VERSION ""

NS_ :

BS_:

BU_: _04_HV_AMS

BO_ 3221225472 VECTOR__INDEPENDENT_SIG_MSG: 0 Vector__XXX
 SG_ AMS_Stack_09_Slave_Cell_Temp_3 : 0|16@0+ (0.1,0) [15|60] "C" Vector__XXX
 SG_ AMS_Stack_09_Slave_Cell_Temp_2 : 0|16@0+ (0.1,0) [15|60] "C" Vector__XXX
 SG_ AMS_Stack_09_Slave_Cell_Temp_1 : 0|16@0+ (0.1,0) [15|60] "C" Vector__XXX
 SG_ AMS_Stack_09_Slave_Cell_Temp_0 : 0|16@0+ (0.1,0) [15|60] "C" Vector__XXX
 SG_ AMS_Stack_10_Slave_Cell_Temp_3 : 0|16@0+ (0.1,0) [15|60] "C" Vector__XXX
 SG_ AMS_Stack_10_Slave_Cell_Temp_2 : 0|16@0+ (0.1,0) [15|60] "C" Vector__XXX
 SG_ AMS_Stack_10_Slave_Cell_Temp_1 : 0|16@0+ (0.1,0) [15|60] "C" Vector__XXX
 SG_ AMS_Stack_10_Slave_Cell_Temp_0 : 0|16@0+ (0.1,0) [15|60] "C" Vector__XXX
 SG_ AMS_Stack_11_Slave_Cell_Temp_3 : 0|16@0+ (0.1,0) [15|60] "C" Vector__XXX
 SG_ AMS_Stack_11_Slave_Cell_Temp_2 : 0|16@0+ (0.1,0) [15|60] "C" Vector__XXX
 SG_ AMS_Stack_11_Slave_Cell_Temp_1 : 0|16@0+ (0.1,0) [15|60] "C" Vector__XXX
 SG_ AMS_Stack_11_Slave_Cell_Temp_0 : 0|16@0+ (0.1,0) [15|60] "C" Vector__XXX

BO_ 1485 AMS_Temps_Stack_08_02: 4 Vector__XXX
 SG_ AMS_Stack_08_Slave_Cell_Temp_5 : 23|16@0+ (0.1,0) [15|60] "C" Vector__XXX
 SG_ AMS_Stack_08_Slave_Cell_Temp_4 : 7|16@0+ (0.1,0) [15|60] "C" Vector__XXX

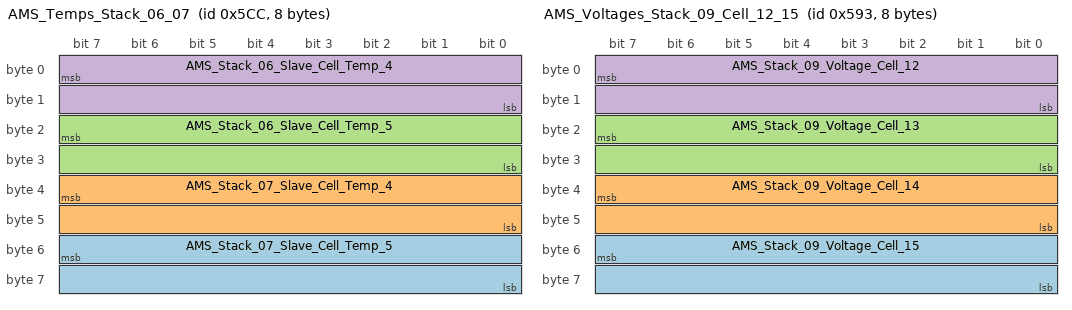
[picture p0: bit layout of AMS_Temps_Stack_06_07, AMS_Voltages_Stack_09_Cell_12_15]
BO_ 1484 AMS_Temps_Stack_06_07: 8 Vector__XXX
 SG_ AMS_Stack_07_Slave_Cell_Temp_5 : 55|16@0+ (0.1,0) [15|60] "C" Vector__XXX
 SG_ AMS_Stack_07_Slave_Cell_Temp_4 : 39|16@0+ (0.1,0) [15|60] "C" Vector__XXX
 SG_ AMS_Stack_06_Slave_Cell_Temp_5 : 23|16@0+ (0.1,0) [15|60] "C" Vector__XXX
 SG_ AMS_Stack_06_Slave_Cell_Temp_4 : 7|16@0+ (0.1,0) [15|60] "C" Vector__XXX

BO_ 1427 AMS_Voltages_Stack_09_Cell_12_15: 8 _04_HV_AMS
 SG_ AMS_Stack_09_Voltage_Cell_15 : 55|16@0- (1,0) [0|0] "mV" Vector__XXX
 SG_ AMS_Stack_09_Voltage_Cell_14 : 39|16@0- (1,0) [0|0] "mV" Vector__XXX
 SG_ AMS_Stack_09_Voltage_Cell_13 : 23|16@0- (1,0) [0|0] "mV" Vector__XXX
 SG_ AMS_Stack_09_Voltage_Cell_12 : 7|16@0- (1,0) [0|0] "mV" Vector__XXX

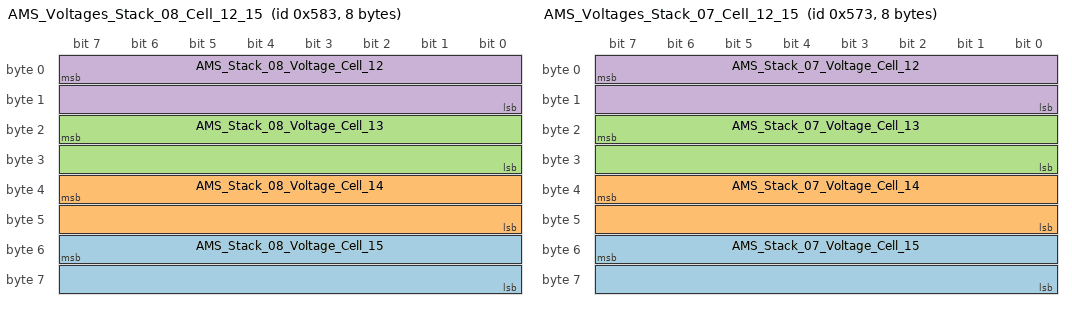
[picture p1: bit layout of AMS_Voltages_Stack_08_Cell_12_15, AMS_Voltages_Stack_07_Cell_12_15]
BO_ 1411 AMS_Voltages_Stack_08_Cell_12_15: 8 _04_HV_AMS
 SG_ AMS_Stack_08_Voltage_Cell_15 : 55|16@0- (1,0) [0|0] "mV" Vector__XXX
 SG_ AMS_Stack_08_Voltage_Cell_14 : 39|16@0- (1,0) [0|0] "mV" Vector__XXX
 SG_ AMS_Stack_08_Voltage_Cell_13 : 23|16@0- (1,0) [0|0] "mV" Vector__XXX
 SG_ AMS_Stack_08_Voltage_Cell_12 : 7|16@0- (1,0) [0|0] "mV" Vector__XXX

BO_ 1395 AMS_Voltages_Stack_07_Cell_12_15: 8 _04_HV_AMS
 SG_ AMS_Stack_07_Voltage_Cell_15 : 55|16@0- (1,0) [0|0] "mV" Vector__XXX
 SG_ AMS_Stack_07_Voltage_Cell_14 : 39|16@0- (1,0) [0|0] "mV" Vector__XXX
 SG_ AMS_Stack_07_Voltage_Cell_13 : 23|16@0- (1,0) [0|0] "mV" Vector__XXX
 SG_ AMS_Stack_07_Voltage_Cell_12 : 7|16@0- (1,0) [0|0] "mV" Vector__XXX

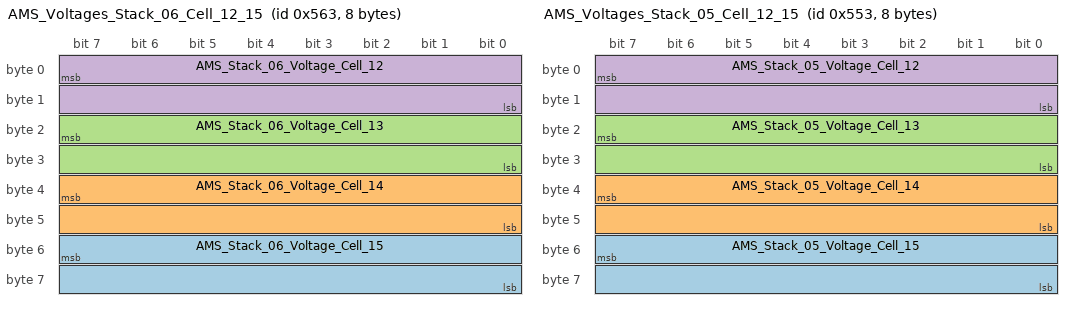
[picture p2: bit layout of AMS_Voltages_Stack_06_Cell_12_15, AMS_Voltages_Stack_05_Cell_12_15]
BO_ 1379 AMS_Voltages_Stack_06_Cell_12_15: 8 _04_HV_AMS
 SG_ AMS_Stack_06_Voltage_Cell_15 : 55|16@0- (1,0) [0|0] "mV" Vector__XXX
 SG_ AMS_Stack_06_Voltage_Cell_14 : 39|16@0- (1,0) [0|0] "mV" Vector__XXX
 SG_ AMS_Stack_06_Voltage_Cell_13 : 23|16@0- (1,0) [0|0] "mV" Vector__XXX
 SG_ AMS_Stack_06_Voltage_Cell_12 : 7|16@0- (1,0) [0|0] "mV" Vector__XXX

BO_ 1363 AMS_Voltages_Stack_05_Cell_12_15: 8 _04_HV_AMS
 SG_ AMS_Stack_05_Voltage_Cell_15 : 55|16@0- (1,0) [0|0] "mV" Vector__XXX
 SG_ AMS_Stack_05_Voltage_Cell_14 : 39|16@0- (1,0) [0|0] "mV" Vector__XXX
 SG_ AMS_Stack_05_Voltage_Cell_13 : 23|16@0- (1,0) [0|0] "mV" Vector__XXX
 SG_ AMS_Stack_05_Voltage_Cell_12 : 7|16@0- (1,0) [0|0] "mV" Vector__XXX

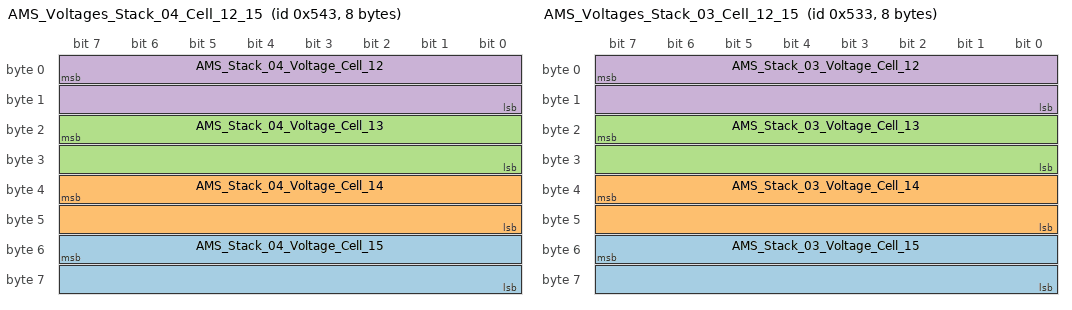
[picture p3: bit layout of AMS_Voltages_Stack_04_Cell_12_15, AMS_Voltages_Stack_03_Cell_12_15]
BO_ 1347 AMS_Voltages_Stack_04_Cell_12_15: 8 _04_HV_AMS
 SG_ AMS_Stack_04_Voltage_Cell_15 : 55|16@0- (1,0) [0|0] "mV" Vector__XXX
 SG_ AMS_Stack_04_Voltage_Cell_14 : 39|16@0- (1,0) [0|0] "mV" Vector__XXX
 SG_ AMS_Stack_04_Voltage_Cell_13 : 23|16@0- (1,0) [0|0] "mV" Vector__XXX
 SG_ AMS_Stack_04_Voltage_Cell_12 : 7|16@0- (1,0) [0|0] "mV" Vector__XXX

BO_ 1331 AMS_Voltages_Stack_03_Cell_12_15: 8 _04_HV_AMS
 SG_ AMS_Stack_03_Voltage_Cell_15 : 55|16@0- (1,0) [0|0] "mV" Vector__XXX
 SG_ AMS_Stack_03_Voltage_Cell_14 : 39|16@0- (1,0) [0|0] "mV" Vector__XXX
 SG_ AMS_Stack_03_Voltage_Cell_13 : 23|16@0- (1,0) [0|0] "mV" Vector__XXX
 SG_ AMS_Stack_03_Voltage_Cell_12 : 7|16@0- (1,0) [0|0] "mV" Vector__XXX

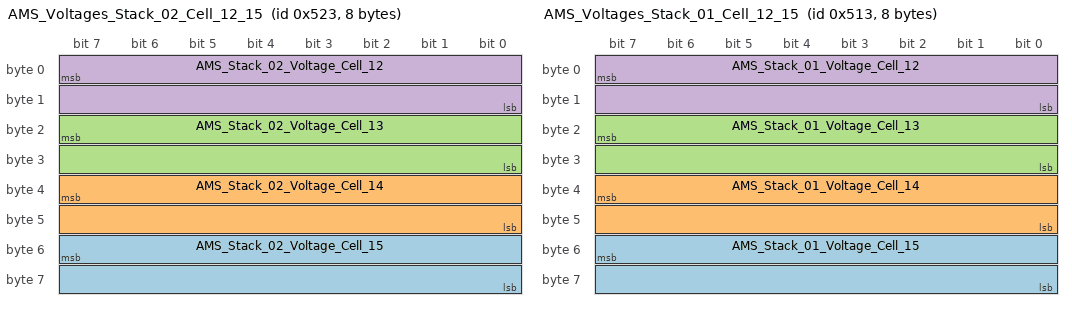
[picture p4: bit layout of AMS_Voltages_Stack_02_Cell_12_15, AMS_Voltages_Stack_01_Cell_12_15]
BO_ 1315 AMS_Voltages_Stack_02_Cell_12_15: 8 _04_HV_AMS
 SG_ AMS_Stack_02_Voltage_Cell_15 : 55|16@0- (1,0) [0|0] "mV" Vector__XXX
 SG_ AMS_Stack_02_Voltage_Cell_14 : 39|16@0- (1,0) [0|0] "mV" Vector__XXX
 SG_ AMS_Stack_02_Voltage_Cell_13 : 23|16@0- (1,0) [0|0] "mV" Vector__XXX
 SG_ AMS_Stack_02_Voltage_Cell_12 : 7|16@0- (1,0) [0|0] "mV" Vector__XXX

BO_ 1299 AMS_Voltages_Stack_01_Cell_12_15: 8 _04_HV_AMS
 SG_ AMS_Stack_01_Voltage_Cell_15 : 55|16@0- (1,0) [0|0] "mV" Vector__XXX
 SG_ AMS_Stack_01_Voltage_Cell_14 : 39|16@0- (1,0) [0|0] "mV" Vector__XXX
 SG_ AMS_Stack_01_Voltage_Cell_13 : 23|16@0- (1,0) [0|0] "mV" Vector__XXX
 SG_ AMS_Stack_01_Voltage_Cell_12 : 7|16@0- (1,0) [0|0] "mV" Vector__XXX

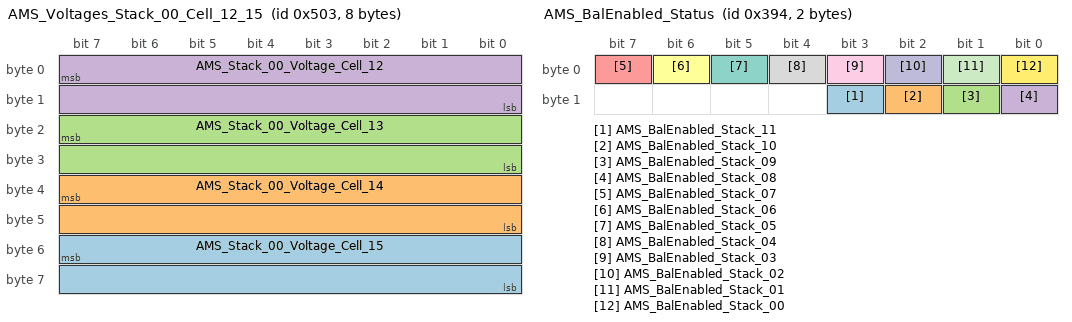
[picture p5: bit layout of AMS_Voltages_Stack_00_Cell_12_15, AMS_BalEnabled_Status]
BO_ 1283 AMS_Voltages_Stack_00_Cell_12_15: 8 _04_HV_AMS
 SG_ AMS_Stack_00_Voltage_Cell_15 : 55|16@0- (1,0) [0|0] "mV" Vector__XXX
 SG_ AMS_Stack_00_Voltage_Cell_14 : 39|16@0- (1,0) [0|0] "mV" Vector__XXX
 SG_ AMS_Stack_00_Voltage_Cell_13 : 23|16@0- (1,0) [0|0] "mV" Vector__XXX
 SG_ AMS_Stack_00_Voltage_Cell_12 : 7|16@0- (1,0) [0|0] "mV" Vector__XXX

BO_ 916 AMS_BalEnabled_Status: 2 Vector__XXX
 SG_ AMS_BalEnabled_Stack_11 : 11|1@0+ (1,0) [0|0] "" Vector__XXX
 SG_ AMS_BalEnabled_Stack_10 : 10|1@0+ (1,0) [0|0] "" Vector__XXX
 SG_ AMS_BalEnabled_Stack_09 : 9|1@0+ (1,0) [0|0] "" Vector__XXX
 SG_ AMS_BalEnabled_Stack_08 : 8|1@0+ (1,0) [0|0] "" Vector__XXX
 SG_ AMS_BalEnabled_Stack_07 : 7|1@0+ (1,0) [0|0] "" Vector__XXX
 SG_ AMS_BalEnabled_Stack_06 : 6|1@0+ (1,0) [0|0] "" Vector__XXX
 SG_ AMS_BalEnabled_Stack_05 : 5|1@0+ (1,0) [0|0] "" Vector__XXX
 SG_ AMS_BalEnabled_Stack_04 : 4|1@0+ (1,0) [0|0] "" Vector__XXX
 SG_ AMS_BalEnabled_Stack_03 : 3|1@0+ (1,0) [0|0] "" Vector__XXX
 SG_ AMS_BalEnabled_Stack_02 : 2|1@0+ (1,0) [0|0] "" Vector__XXX
 SG_ AMS_BalEnabled_Stack_01 : 1|1@0+ (1,0) [0|0] "" Vector__XXX
 SG_ AMS_BalEnabled_Stack_00 : 0|1@0+ (1,0) [0|0] "" Vector__XXX

BO_ 1504 AMS_Diagnostic_Data_Stack_00: 5 _04_HV_AMS
 SG_ AMS_Stack_00_Temp_Internal : 7|16@0- (0.1,0) [0|0] "°C" Vector__XXX
 SG_ AMS_Stack_00_Scan_Count : 39|8@0+ (1,0) [0|0] "" Vector__XXX
 SG_ AMS_Stack_00_Ref_Voltage : 23|16@0+ (1,0) [0|0] "mV" Vector__XXX

BO_ 1505 AMS_Diagnostic_Data_Stack_01: 5 _04_HV_AMS
 SG_ AMS_Stack_01_Temp_Internal : 7|16@0- (0.1,0) [0|0] "°C" Vector__XXX
 SG_ AMS_Stack_01_Scan_Count : 39|8@0+ (1,0) [0|0] "" Vector__XXX
 SG_ AMS_Stack_01_Ref_Voltage : 23|16@0+ (1,0) [0|0] "mV" Vector__XXX

BO_ 1506 AMS_Diagnostic_Data_Stack_02: 5 _04_HV_AMS
 SG_ AMS_Stack_02_Temp_Internal : 7|16@0- (0.1,0) [0|0] "°C" Vector__XXX
 SG_ AMS_Stack_02_Scan_Count : 39|8@0+ (1,0) [0|0] "" Vector__XXX
 SG_ AMS_Stack_02_Ref_Voltage : 23|16@0+ (1,0) [0|0] "mV" Vector__XXX

BO_ 1507 AMS_Diagnostic_Data_Stack_03: 5 _04_HV_AMS
 SG_ AMS_Stack_03_Temp_Internal : 7|16@0- (0.1,0) [0|0] "°C" Vector__XXX
 SG_ AMS_Stack_03_Scan_Count : 39|8@0+ (1,0) [0|0] "" Vector__XXX
 SG_ AMS_Stack_03_Ref_Voltage : 23|16@0+ (1,0) [0|0] "mV" Vector__XXX

BO_ 1508 AMS_Diagnostic_Data_Stack_04: 5 _04_HV_AMS
 SG_ AMS_Stack_04_Temp_Internal : 7|16@0- (0.1,0) [0|0] "°C" Vector__XXX
 SG_ AMS_Stack_04_Scan_Count : 39|8@0+ (1,0) [0|0] "" Vector__XXX
 SG_ AMS_Stack_04_Ref_Voltage : 23|16@0+ (1,0) [0|0] "mV" Vector__XXX

BO_ 1509 AMS_Diagnostic_Data_Stack_05: 5 _04_HV_AMS
 SG_ AMS_Stack_05_Temp_Internal : 7|16@0- (0.1,0) [0|0] "°C" Vector__XXX
 SG_ AMS_Stack_05_Scan_Count : 39|8@0+ (1,0) [0|0] "" Vector__XXX
 SG_ AMS_Stack_05_Ref_Voltage : 23|16@0+ (1,0) [0|0] "mV" Vector__XXX

BO_ 1510 AMS_Diagnostic_Data_Stack_06: 5 _04_HV_AMS
 SG_ AMS_Stack_06_Temp_Internal : 7|16@0- (0.1,0) [0|0] "°C" Vector__XXX
 SG_ AMS_Stack_06_Scan_Count : 39|8@0+ (1,0) [0|0] "" Vector__XXX
 SG_ AMS_Stack_06_Ref_Voltage : 23|16@0+ (1,0) [0|0] "mV" Vector__XXX

BO_ 1511 AMS_Diagnostic_Data_Stack_07: 5 _04_HV_AMS
 SG_ AMS_Stack_07_Temp_Internal : 7|16@0- (0.1,0) [0|0] "°C" Vector__XXX
 SG_ AMS_Stack_07_Scan_Count : 39|8@0+ (1,0) [0|0] "" Vector__XXX
 SG_ AMS_Stack_07_Ref_Voltage : 23|16@0+ (1,0) [0|0] "mV" Vector__XXX

BO_ 1512 AMS_Diagnostic_Data_Stack_08: 5 _04_HV_AMS
 SG_ AMS_Stack_08_Temp_Internal : 7|16@0- (0.1,0) [0|0] "°C" Vector__XXX
 SG_ AMS_Stack_08_Scan_Count : 39|8@0+ (1,0) [0|0] "" Vector__XXX
 SG_ AMS_Stack_08_Ref_Voltage : 23|16@0+ (1,0) [0|0] "mV" Vector__XXX

BO_ 1513 AMS_Diagnostic_Data_Stack_09: 5 _04_HV_AMS
 SG_ AMS_Stack_09_Temp_Internal : 7|16@0- (0.1,0) [0|0] "°C" Vector__XXX
 SG_ AMS_Stack_09_Scan_Count : 39|8@0+ (1,0) [0|0] "" Vector__XXX
 SG_ AMS_Stack_09_Ref_Voltage : 23|16@0+ (1,0) [0|0] "mV" Vector__XXX

BO_ 1514 AMS_Diagnostic_Data_Stack_10: 5 _04_HV_AMS
 SG_ AMS_Stack_10_Temp_Internal : 7|16@0- (0.1,0) [0|0] "°C" Vector__XXX
 SG_ AMS_Stack_10_Scan_Count : 39|8@0+ (1,0) [0|0] "" Vector__XXX
 SG_ AMS_Stack_10_Ref_Voltage : 23|16@0+ (1,0) [0|0] "mV" Vector__XXX

BO_ 1515 AMS_Diagnostic_Data_Stack_11: 5 _04_HV_AMS
 SG_ AMS_Stack_11_Temp_Internal : 7|16@0- (0.1,0) [0|0] "°C" Vector__XXX
 SG_ AMS_Stack_11_Scan_Count : 39|8@0+ (1,0) [0|0] "" Vector__XXX
 SG_ AMS_Stack_11_Ref_Voltage : 23|16@0+ (1,0) [0|0] "mV" Vector__XXX

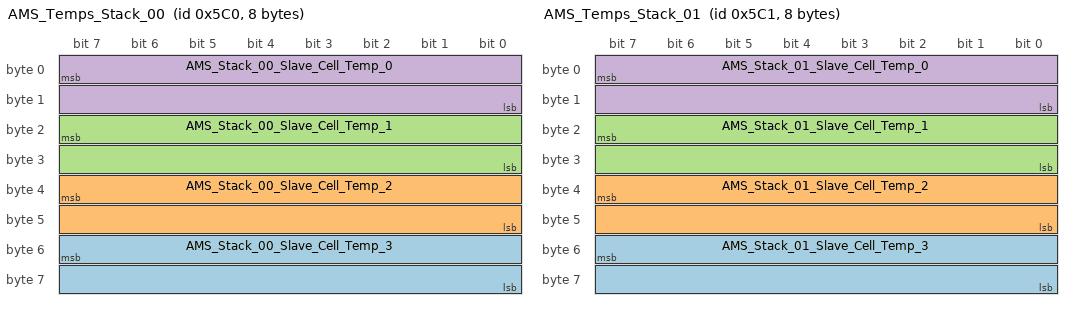
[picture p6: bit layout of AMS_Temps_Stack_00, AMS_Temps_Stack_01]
BO_ 1472 AMS_Temps_Stack_00: 8 _04_HV_AMS
 SG_ AMS_Stack_00_Slave_Cell_Temp_3 : 55|16@0+ (0.1,0) [15|60] "C" Vector__XXX
 SG_ AMS_Stack_00_Slave_Cell_Temp_2 : 39|16@0+ (0.1,0) [15|60] "C" Vector__XXX
 SG_ AMS_Stack_00_Slave_Cell_Temp_1 : 23|16@0+ (0.1,0) [15|60] "C" Vector__XXX
 SG_ AMS_Stack_00_Slave_Cell_Temp_0 : 7|16@0+ (0.1,0) [15|60] "C" Vector__XXX

BO_ 1473 AMS_Temps_Stack_01: 8 _04_HV_AMS
 SG_ AMS_Stack_01_Slave_Cell_Temp_3 : 55|16@0+ (0.1,0) [15|60] "C" Vector__XXX
 SG_ AMS_Stack_01_Slave_Cell_Temp_2 : 39|16@0+ (0.1,0) [15|60] "C" Vector__XXX
 SG_ AMS_Stack_01_Slave_Cell_Temp_1 : 23|16@0+ (0.1,0) [15|60] "C" Vector__XXX
 SG_ AMS_Stack_01_Slave_Cell_Temp_0 : 7|16@0+ (0.1,0) [15|60] "C" Vector__XXX

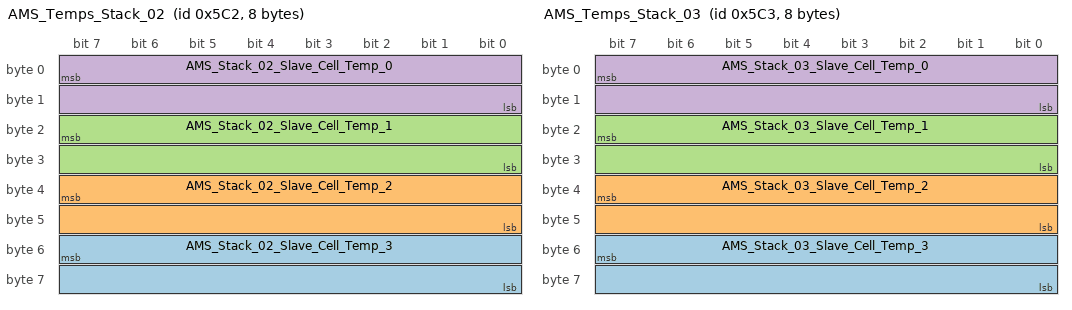
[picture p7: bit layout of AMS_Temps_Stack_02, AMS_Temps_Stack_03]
BO_ 1474 AMS_Temps_Stack_02: 8 _04_HV_AMS
 SG_ AMS_Stack_02_Slave_Cell_Temp_3 : 55|16@0+ (0.1,0) [15|60] "C" Vector__XXX
 SG_ AMS_Stack_02_Slave_Cell_Temp_2 : 39|16@0+ (0.1,0) [15|60] "C" Vector__XXX
 SG_ AMS_Stack_02_Slave_Cell_Temp_1 : 23|16@0+ (0.1,0) [15|60] "C" Vector__XXX
 SG_ AMS_Stack_02_Slave_Cell_Temp_0 : 7|16@0+ (0.1,0) [15|60] "C" Vector__XXX

BO_ 1475 AMS_Temps_Stack_03: 8 _04_HV_AMS
 SG_ AMS_Stack_03_Slave_Cell_Temp_3 : 55|16@0+ (0.1,0) [15|60] "C" Vector__XXX
 SG_ AMS_Stack_03_Slave_Cell_Temp_2 : 39|16@0+ (0.1,0) [15|60] "C" Vector__XXX
 SG_ AMS_Stack_03_Slave_Cell_Temp_1 : 23|16@0+ (0.1,0) [15|60] "C" Vector__XXX
 SG_ AMS_Stack_03_Slave_Cell_Temp_0 : 7|16@0+ (0.1,0) [15|60] "C" Vector__XXX

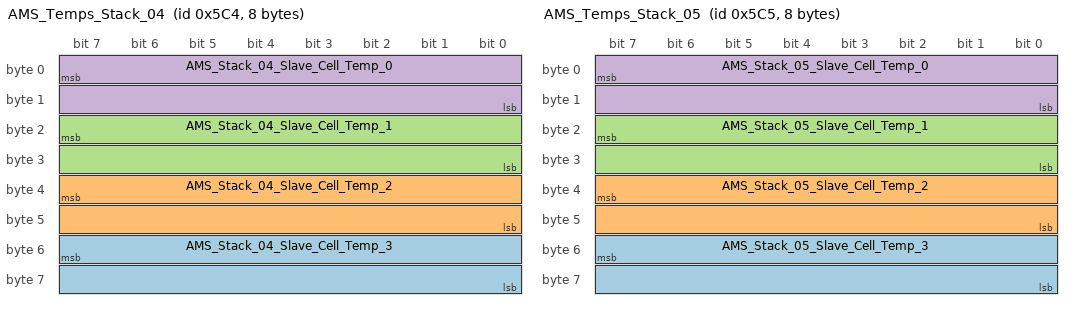
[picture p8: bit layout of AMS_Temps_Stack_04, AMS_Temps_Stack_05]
BO_ 1476 AMS_Temps_Stack_04: 8 _04_HV_AMS
 SG_ AMS_Stack_04_Slave_Cell_Temp_3 : 55|16@0+ (0.1,0) [15|60] "C" Vector__XXX
 SG_ AMS_Stack_04_Slave_Cell_Temp_2 : 39|16@0+ (0.1,0) [15|60] "C" Vector__XXX
 SG_ AMS_Stack_04_Slave_Cell_Temp_1 : 23|16@0+ (0.1,0) [15|60] "C" Vector__XXX
 SG_ AMS_Stack_04_Slave_Cell_Temp_0 : 7|16@0+ (0.1,0) [15|60] "C" Vector__XXX

BO_ 1477 AMS_Temps_Stack_05: 8 _04_HV_AMS
 SG_ AMS_Stack_05_Slave_Cell_Temp_3 : 55|16@0+ (0.1,0) [15|60] "C" Vector__XXX
 SG_ AMS_Stack_05_Slave_Cell_Temp_2 : 39|16@0+ (0.1,0) [15|60] "C" Vector__XXX
 SG_ AMS_Stack_05_Slave_Cell_Temp_1 : 23|16@0+ (0.1,0) [15|60] "C" Vector__XXX
 SG_ AMS_Stack_05_Slave_Cell_Temp_0 : 7|16@0+ (0.1,0) [15|60] "C" Vector__XXX

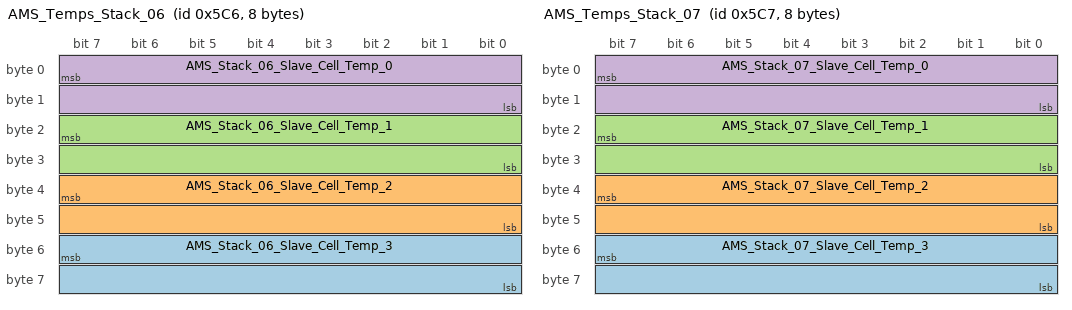
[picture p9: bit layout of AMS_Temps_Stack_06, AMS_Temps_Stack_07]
BO_ 1478 AMS_Temps_Stack_06: 8 _04_HV_AMS
 SG_ AMS_Stack_06_Slave_Cell_Temp_3 : 55|16@0+ (0.1,0) [15|60] "C" Vector__XXX
 SG_ AMS_Stack_06_Slave_Cell_Temp_2 : 39|16@0+ (0.1,0) [15|60] "C" Vector__XXX
 SG_ AMS_Stack_06_Slave_Cell_Temp_1 : 23|16@0+ (0.1,0) [15|60] "C" Vector__XXX
 SG_ AMS_Stack_06_Slave_Cell_Temp_0 : 7|16@0+ (0.1,0) [15|60] "C" Vector__XXX

BO_ 1479 AMS_Temps_Stack_07: 8 _04_HV_AMS
 SG_ AMS_Stack_07_Slave_Cell_Temp_3 : 55|16@0+ (0.1,0) [15|60] "C" Vector__XXX
 SG_ AMS_Stack_07_Slave_Cell_Temp_2 : 39|16@0+ (0.1,0) [15|60] "C" Vector__XXX
 SG_ AMS_Stack_07_Slave_Cell_Temp_1 : 23|16@0+ (0.1,0) [15|60] "C" Vector__XXX
 SG_ AMS_Stack_07_Slave_Cell_Temp_0 : 7|16@0+ (0.1,0) [15|60] "C" Vector__XXX

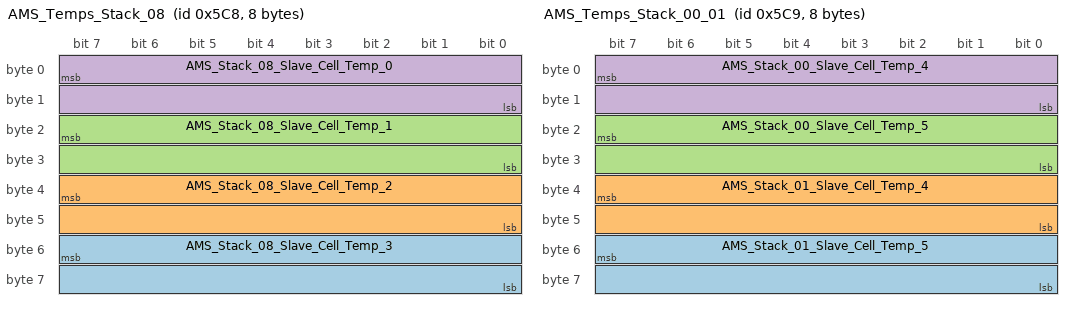
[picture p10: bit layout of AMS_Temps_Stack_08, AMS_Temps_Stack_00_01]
BO_ 1480 AMS_Temps_Stack_08: 8 _04_HV_AMS
 SG_ AMS_Stack_08_Slave_Cell_Temp_3 : 55|16@0+ (0.1,0) [15|60] "C" Vector__XXX
 SG_ AMS_Stack_08_Slave_Cell_Temp_2 : 39|16@0+ (0.1,0) [15|60] "C" Vector__XXX
 SG_ AMS_Stack_08_Slave_Cell_Temp_1 : 23|16@0+ (0.1,0) [15|60] "C" Vector__XXX
 SG_ AMS_Stack_08_Slave_Cell_Temp_0 : 7|16@0+ (0.1,0) [15|60] "C" Vector__XXX

BO_ 1481 AMS_Temps_Stack_00_01: 8 _04_HV_AMS
 SG_ AMS_Stack_01_Slave_Cell_Temp_5 : 55|16@0+ (0.1,0) [15|60] "C" Vector__XXX
 SG_ AMS_Stack_01_Slave_Cell_Temp_4 : 39|16@0+ (0.1,0) [15|60] "C" Vector__XXX
 SG_ AMS_Stack_00_Slave_Cell_Temp_5 : 23|16@0+ (0.1,0) [15|60] "C" Vector__XXX
 SG_ AMS_Stack_00_Slave_Cell_Temp_4 : 7|16@0+ (0.1,0) [15|60] "C" Vector__XXX

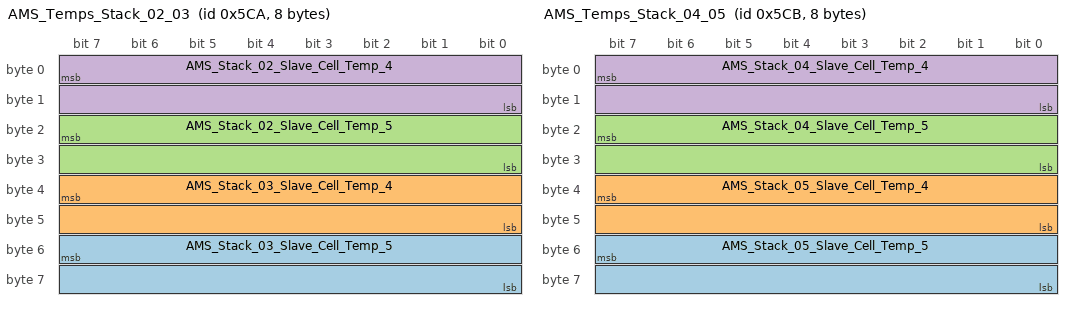
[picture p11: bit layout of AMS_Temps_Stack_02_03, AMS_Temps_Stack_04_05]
BO_ 1482 AMS_Temps_Stack_02_03: 8 _04_HV_AMS
 SG_ AMS_Stack_03_Slave_Cell_Temp_5 : 55|16@0+ (0.1,0) [15|60] "C" Vector__XXX
 SG_ AMS_Stack_03_Slave_Cell_Temp_4 : 39|16@0+ (0.1,0) [15|60] "C" Vector__XXX
 SG_ AMS_Stack_02_Slave_Cell_Temp_5 : 23|16@0+ (0.1,0) [15|60] "C" Vector__XXX
 SG_ AMS_Stack_02_Slave_Cell_Temp_4 : 7|16@0+ (0.1,0) [15|60] "C" Vector__XXX

BO_ 1483 AMS_Temps_Stack_04_05: 8 _04_HV_AMS
 SG_ AMS_Stack_05_Slave_Cell_Temp_5 : 55|16@0+ (0.1,0) [15|60] "C" Vector__XXX
 SG_ AMS_Stack_05_Slave_Cell_Temp_4 : 39|16@0+ (0.1,0) [15|60] "C" Vector__XXX
 SG_ AMS_Stack_04_Slave_Cell_Temp_5 : 23|16@0+ (0.1,0) [15|60] "C" Vector__XXX
 SG_ AMS_Stack_04_Slave_Cell_Temp_4 : 7|16@0+ (0.1,0) [15|60] "C" Vector__XXX

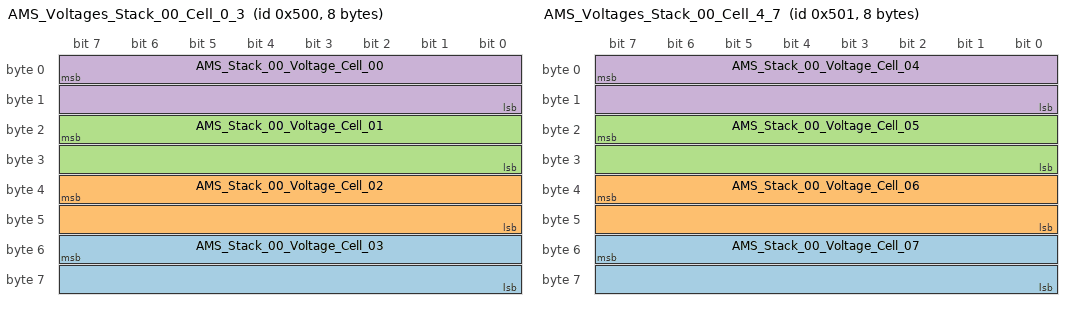
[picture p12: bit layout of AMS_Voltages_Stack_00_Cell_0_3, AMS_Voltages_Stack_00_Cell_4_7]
BO_ 1280 AMS_Voltages_Stack_00_Cell_0_3: 8 _04_HV_AMS
 SG_ AMS_Stack_00_Voltage_Cell_03 : 55|16@0- (1,0) [0|0] "mV" Vector__XXX
 SG_ AMS_Stack_00_Voltage_Cell_02 : 39|16@0- (1,0) [0|0] "mV" Vector__XXX
 SG_ AMS_Stack_00_Voltage_Cell_01 : 23|16@0- (1,0) [0|0] "mV" Vector__XXX
 SG_ AMS_Stack_00_Voltage_Cell_00 : 7|16@0- (1,0) [0|0] "mV" Vector__XXX

BO_ 1281 AMS_Voltages_Stack_00_Cell_4_7: 8 _04_HV_AMS
 SG_ AMS_Stack_00_Voltage_Cell_07 : 55|16@0- (1,0) [0|0] "mV" Vector__XXX
 SG_ AMS_Stack_00_Voltage_Cell_06 : 39|16@0- (1,0) [0|0] "mV" Vector__XXX
 SG_ AMS_Stack_00_Voltage_Cell_05 : 23|16@0- (1,0) [0|0] "mV" Vector__XXX
 SG_ AMS_Stack_00_Voltage_Cell_04 : 7|16@0- (1,0) [0|0] "mV" Vector__XXX

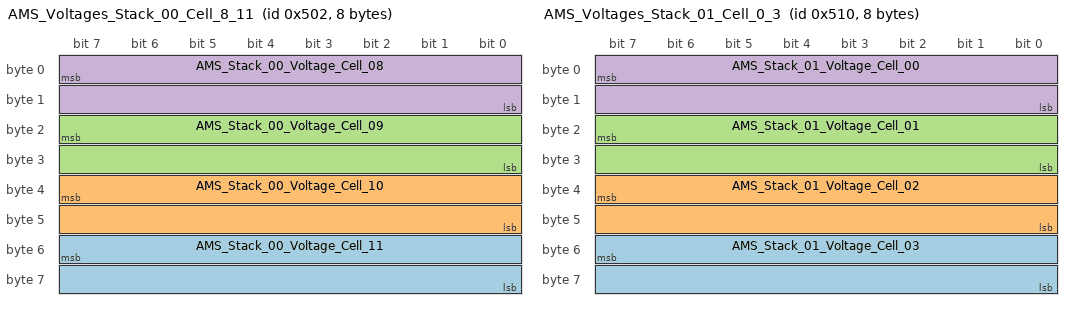
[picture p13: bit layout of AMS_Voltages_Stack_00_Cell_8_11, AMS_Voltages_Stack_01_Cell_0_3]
BO_ 1282 AMS_Voltages_Stack_00_Cell_8_11: 8 _04_HV_AMS
 SG_ AMS_Stack_00_Voltage_Cell_11 : 55|16@0- (1,0) [0|0] "mV" Vector__XXX
 SG_ AMS_Stack_00_Voltage_Cell_10 : 39|16@0- (1,0) [0|0] "mV" Vector__XXX
 SG_ AMS_Stack_00_Voltage_Cell_09 : 23|16@0- (1,0) [0|0] "mV" Vector__XXX
 SG_ AMS_Stack_00_Voltage_Cell_08 : 7|16@0- (1,0) [0|0] "mV" Vector__XXX

BO_ 1296 AMS_Voltages_Stack_01_Cell_0_3: 8 _04_HV_AMS
 SG_ AMS_Stack_01_Voltage_Cell_03 : 55|16@0- (1,0) [0|0] "mV" Vector__XXX
 SG_ AMS_Stack_01_Voltage_Cell_02 : 39|16@0- (1,0) [0|0] "mV" Vector__XXX
 SG_ AMS_Stack_01_Voltage_Cell_01 : 23|16@0- (1,0) [0|0] "mV" Vector__XXX
 SG_ AMS_Stack_01_Voltage_Cell_00 : 7|16@0- (1,0) [0|0] "mV" Vector__XXX

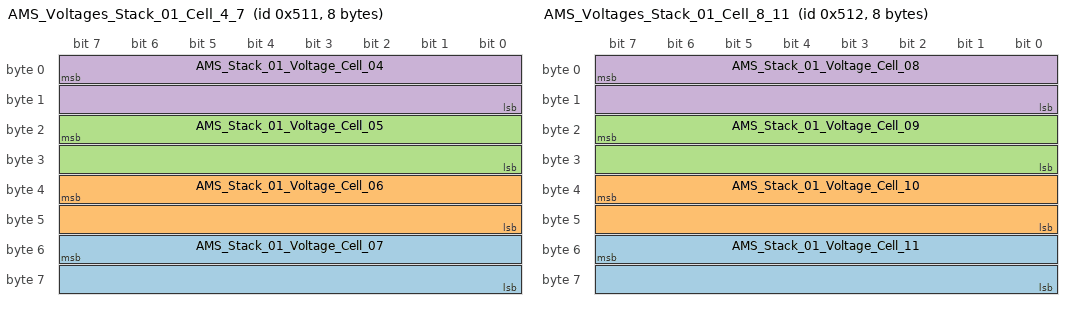
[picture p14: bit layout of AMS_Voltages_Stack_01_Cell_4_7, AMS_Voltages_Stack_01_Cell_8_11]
BO_ 1297 AMS_Voltages_Stack_01_Cell_4_7: 8 _04_HV_AMS
 SG_ AMS_Stack_01_Voltage_Cell_07 : 55|16@0- (1,0) [0|0] "mV" Vector__XXX
 SG_ AMS_Stack_01_Voltage_Cell_06 : 39|16@0- (1,0) [0|0] "mV" Vector__XXX
 SG_ AMS_Stack_01_Voltage_Cell_05 : 23|16@0- (1,0) [0|0] "mV" Vector__XXX
 SG_ AMS_Stack_01_Voltage_Cell_04 : 7|16@0- (1,0) [0|0] "mV" Vector__XXX

BO_ 1298 AMS_Voltages_Stack_01_Cell_8_11: 8 _04_HV_AMS
 SG_ AMS_Stack_01_Voltage_Cell_11 : 55|16@0- (1,0) [0|0] "mV" Vector__XXX
 SG_ AMS_Stack_01_Voltage_Cell_10 : 39|16@0- (1,0) [0|0] "mV" Vector__XXX
 SG_ AMS_Stack_01_Voltage_Cell_09 : 23|16@0- (1,0) [0|0] "mV" Vector__XXX
 SG_ AMS_Stack_01_Voltage_Cell_08 : 7|16@0- (1,0) [0|0] "mV" Vector__XXX

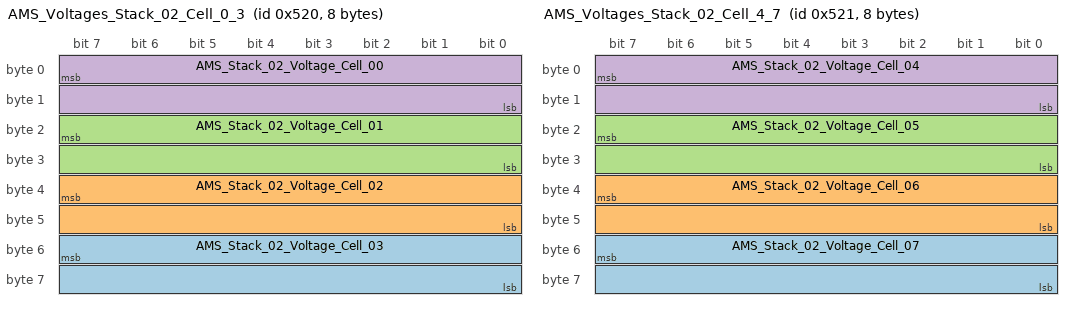
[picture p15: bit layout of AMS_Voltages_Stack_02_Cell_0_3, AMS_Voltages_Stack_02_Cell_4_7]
BO_ 1312 AMS_Voltages_Stack_02_Cell_0_3: 8 _04_HV_AMS
 SG_ AMS_Stack_02_Voltage_Cell_03 : 55|16@0- (1,0) [0|0] "mV" Vector__XXX
 SG_ AMS_Stack_02_Voltage_Cell_02 : 39|16@0- (1,0) [0|0] "mV" Vector__XXX
 SG_ AMS_Stack_02_Voltage_Cell_01 : 23|16@0- (1,0) [0|0] "mV" Vector__XXX
 SG_ AMS_Stack_02_Voltage_Cell_00 : 7|16@0- (1,0) [0|0] "mV" Vector__XXX

BO_ 1313 AMS_Voltages_Stack_02_Cell_4_7: 8 _04_HV_AMS
 SG_ AMS_Stack_02_Voltage_Cell_07 : 55|16@0- (1,0) [0|0] "mV" Vector__XXX
 SG_ AMS_Stack_02_Voltage_Cell_06 : 39|16@0- (1,0) [0|0] "mV" Vector__XXX
 SG_ AMS_Stack_02_Voltage_Cell_05 : 23|16@0- (1,0) [0|0] "mV" Vector__XXX
 SG_ AMS_Stack_02_Voltage_Cell_04 : 7|16@0- (1,0) [0|0] "mV" Vector__XXX

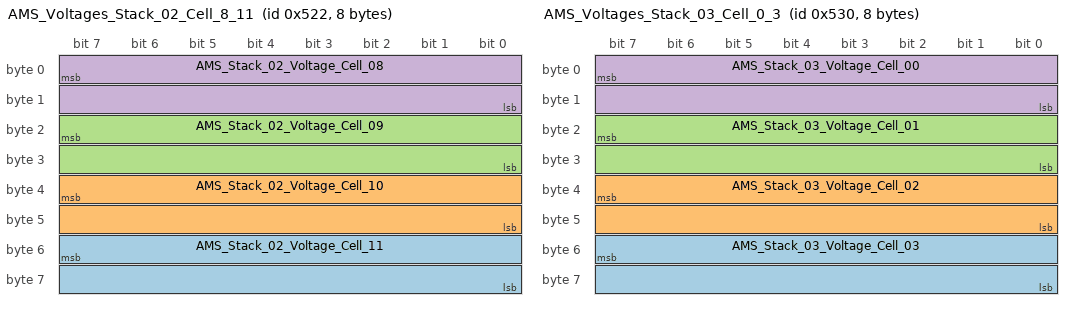
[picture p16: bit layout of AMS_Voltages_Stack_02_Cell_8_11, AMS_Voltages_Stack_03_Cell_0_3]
BO_ 1314 AMS_Voltages_Stack_02_Cell_8_11: 8 _04_HV_AMS
 SG_ AMS_Stack_02_Voltage_Cell_11 : 55|16@0- (1,0) [0|0] "mV" Vector__XXX
 SG_ AMS_Stack_02_Voltage_Cell_10 : 39|16@0- (1,0) [0|0] "mV" Vector__XXX
 SG_ AMS_Stack_02_Voltage_Cell_09 : 23|16@0- (1,0) [0|0] "mV" Vector__XXX
 SG_ AMS_Stack_02_Voltage_Cell_08 : 7|16@0- (1,0) [0|0] "mV" Vector__XXX

BO_ 1328 AMS_Voltages_Stack_03_Cell_0_3: 8 _04_HV_AMS
 SG_ AMS_Stack_03_Voltage_Cell_03 : 55|16@0- (1,0) [0|0] "mV" Vector__XXX
 SG_ AMS_Stack_03_Voltage_Cell_02 : 39|16@0- (1,0) [0|0] "mV" Vector__XXX
 SG_ AMS_Stack_03_Voltage_Cell_01 : 23|16@0- (1,0) [0|0] "mV" Vector__XXX
 SG_ AMS_Stack_03_Voltage_Cell_00 : 7|16@0- (1,0) [0|0] "mV" Vector__XXX

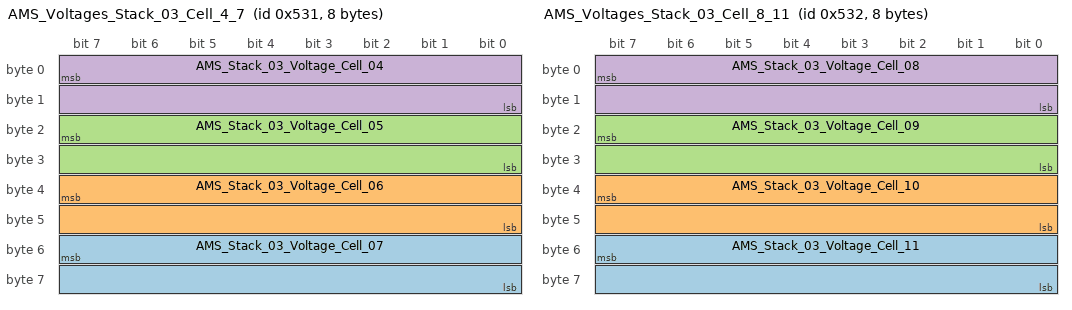
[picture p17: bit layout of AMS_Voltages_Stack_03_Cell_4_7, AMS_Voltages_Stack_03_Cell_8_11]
BO_ 1329 AMS_Voltages_Stack_03_Cell_4_7: 8 _04_HV_AMS
 SG_ AMS_Stack_03_Voltage_Cell_07 : 55|16@0- (1,0) [0|0] "mV" Vector__XXX
 SG_ AMS_Stack_03_Voltage_Cell_06 : 39|16@0- (1,0) [0|0] "mV" Vector__XXX
 SG_ AMS_Stack_03_Voltage_Cell_05 : 23|16@0- (1,0) [0|0] "mV" Vector__XXX
 SG_ AMS_Stack_03_Voltage_Cell_04 : 7|16@0- (1,0) [0|0] "mV" Vector__XXX

BO_ 1330 AMS_Voltages_Stack_03_Cell_8_11: 8 _04_HV_AMS
 SG_ AMS_Stack_03_Voltage_Cell_11 : 55|16@0- (1,0) [0|0] "mV" Vector__XXX
 SG_ AMS_Stack_03_Voltage_Cell_10 : 39|16@0- (1,0) [0|0] "mV" Vector__XXX
 SG_ AMS_Stack_03_Voltage_Cell_09 : 23|16@0- (1,0) [0|0] "mV" Vector__XXX
 SG_ AMS_Stack_03_Voltage_Cell_08 : 7|16@0- (1,0) [0|0] "mV" Vector__XXX

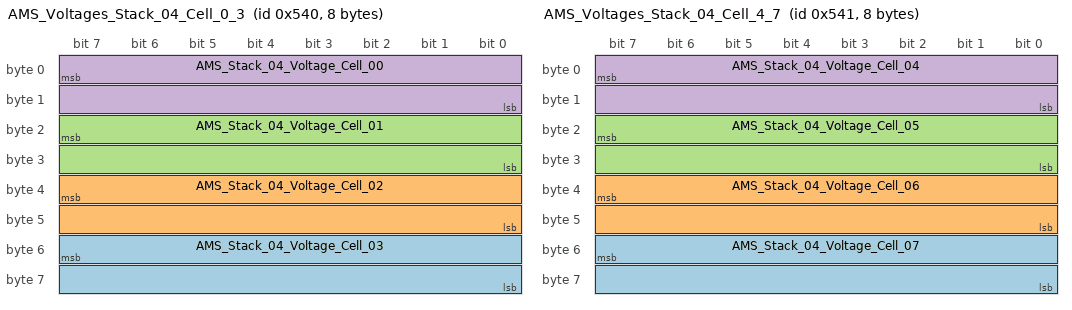
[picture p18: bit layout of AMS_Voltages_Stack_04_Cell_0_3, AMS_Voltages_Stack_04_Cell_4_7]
BO_ 1344 AMS_Voltages_Stack_04_Cell_0_3: 8 _04_HV_AMS
 SG_ AMS_Stack_04_Voltage_Cell_03 : 55|16@0- (1,0) [0|0] "mV" Vector__XXX
 SG_ AMS_Stack_04_Voltage_Cell_02 : 39|16@0- (1,0) [0|0] "mV" Vector__XXX
 SG_ AMS_Stack_04_Voltage_Cell_01 : 23|16@0- (1,0) [0|0] "mV" Vector__XXX
 SG_ AMS_Stack_04_Voltage_Cell_00 : 7|16@0- (1,0) [0|0] "mV" Vector__XXX

BO_ 1345 AMS_Voltages_Stack_04_Cell_4_7: 8 _04_HV_AMS
 SG_ AMS_Stack_04_Voltage_Cell_07 : 55|16@0- (1,0) [0|0] "mV" Vector__XXX
 SG_ AMS_Stack_04_Voltage_Cell_06 : 39|16@0- (1,0) [0|0] "mV" Vector__XXX
 SG_ AMS_Stack_04_Voltage_Cell_05 : 23|16@0- (1,0) [0|0] "mV" Vector__XXX
 SG_ AMS_Stack_04_Voltage_Cell_04 : 7|16@0- (1,0) [0|0] "mV" Vector__XXX

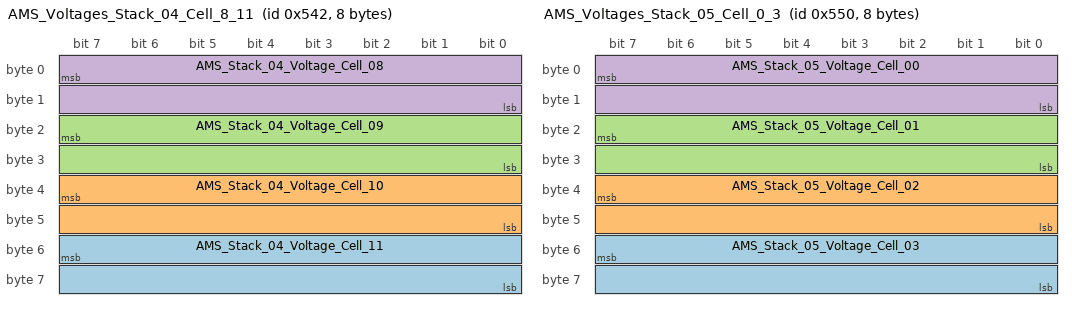
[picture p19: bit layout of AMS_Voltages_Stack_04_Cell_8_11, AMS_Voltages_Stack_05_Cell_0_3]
BO_ 1346 AMS_Voltages_Stack_04_Cell_8_11: 8 _04_HV_AMS
 SG_ AMS_Stack_04_Voltage_Cell_11 : 55|16@0- (1,0) [0|0] "mV" Vector__XXX
 SG_ AMS_Stack_04_Voltage_Cell_10 : 39|16@0- (1,0) [0|0] "mV" Vector__XXX
 SG_ AMS_Stack_04_Voltage_Cell_09 : 23|16@0- (1,0) [0|0] "mV" Vector__XXX
 SG_ AMS_Stack_04_Voltage_Cell_08 : 7|16@0- (1,0) [0|0] "mV" Vector__XXX

BO_ 1360 AMS_Voltages_Stack_05_Cell_0_3: 8 _04_HV_AMS
 SG_ AMS_Stack_05_Voltage_Cell_03 : 55|16@0- (1,0) [0|0] "mV" Vector__XXX
 SG_ AMS_Stack_05_Voltage_Cell_02 : 39|16@0- (1,0) [0|0] "mV" Vector__XXX
 SG_ AMS_Stack_05_Voltage_Cell_01 : 23|16@0- (1,0) [0|0] "mV" Vector__XXX
 SG_ AMS_Stack_05_Voltage_Cell_00 : 7|16@0- (1,0) [0|0] "mV" Vector__XXX

BO_ 1361 AMS_Voltages_Stack_05_Cell_4_7: 8 _04_HV_AMS
 SG_ AMS_Stack_05_Voltage_Cell_07 : 55|16@0- (1,0) [0|0] "mV" Vector__XXX
 SG_ AMS_Stack_05_Voltage_Cell_06 : 39|16@0- (1,0) [0|0] "mV" Vector__XXX
 SG_ AMS_Stack_05_Voltage_Cell_05 : 23|16@0- (1,0) [0|0] "mV" Vector__XXX
 SG_ AMS_Stack_05_Voltage_Cell_04 : 7|16@0- (1,0) [0|0] "mV" Vector__XXX

BO_ 1362 AMS_Voltages_Stack_05_Cell_8_11: 8 _04_HV_AMS
 SG_ AMS_Stack_05_Voltage_Cell_11 : 55|16@0- (1,0) [0|0] "mV" Vector__XXX
 SG_ AMS_Stack_05_Voltage_Cell_10 : 39|16@0- (1,0) [0|0] "mV" Vector__XXX
 SG_ AMS_Stack_05_Voltage_Cell_09 : 23|16@0- (1,0) [0|0] "mV" Vector__XXX
 SG_ AMS_Stack_05_Voltage_Cell_08 : 7|16@0- (1,0) [0|0] "mV" Vector__XXX

BO_ 1376 AMS_Voltages_Stack_06_Cell_0_3: 8 _04_HV_AMS
 SG_ AMS_Stack_06_Voltage_Cell_03 : 55|16@0- (1,0) [0|0] "mV" Vector__XXX
 SG_ AMS_Stack_06_Voltage_Cell_02 : 39|16@0- (1,0) [0|0] "mV" Vector__XXX
 SG_ AMS_Stack_06_Voltage_Cell_01 : 23|16@0- (1,0) [0|0] "mV" Vector__XXX
 SG_ AMS_Stack_06_Voltage_Cell_00 : 7|16@0- (1,0) [0|0] "mV" Vector__XXX

BO_ 1377 AMS_Voltages_Stack_06_Cell_4_7: 8 _04_HV_AMS
 SG_ AMS_Stack_06_Voltage_Cell_07 : 55|16@0- (1,0) [0|0] "mV" Vector__XXX
 SG_ AMS_Stack_06_Voltage_Cell_06 : 39|16@0- (1,0) [0|0] "mV" Vector__XXX
 SG_ AMS_Stack_06_Voltage_Cell_05 : 23|16@0- (1,0) [0|0] "mV" Vector__XXX
 SG_ AMS_Stack_06_Voltage_Cell_04 : 7|16@0- (1,0) [0|0] "mV" Vector__XXX

BO_ 1378 AMS_Voltages_Stack_06_Cell_8_11: 8 _04_HV_AMS
 SG_ AMS_Stack_06_Voltage_Cell_11 : 55|16@0- (1,0) [0|0] "mV" Vector__XXX
 SG_ AMS_Stack_06_Voltage_Cell_10 : 39|16@0- (1,0) [0|0] "mV" Vector__XXX
 SG_ AMS_Stack_06_Voltage_Cell_09 : 23|16@0- (1,0) [0|0] "mV" Vector__XXX
 SG_ AMS_Stack_06_Voltage_Cell_08 : 7|16@0- (1,0) [0|0] "mV" Vector__XXX

BO_ 1392 AMS_Voltages_Stack_07_Cell_0_3: 8 _04_HV_AMS
 SG_ AMS_Stack_07_Voltage_Cell_03 : 55|16@0- (1,0) [0|0] "mV" Vector__XXX
 SG_ AMS_Stack_07_Voltage_Cell_02 : 39|16@0- (1,0) [0|0] "mV" Vector__XXX
 SG_ AMS_Stack_07_Voltage_Cell_01 : 23|16@0- (1,0) [0|0] "mV" Vector__XXX
 SG_ AMS_Stack_07_Voltage_Cell_00 : 7|16@0- (1,0) [0|0] "mV" Vector__XXX

BO_ 1393 AMS_Voltages_Stack_07_Cell_4_7: 8 _04_HV_AMS
 SG_ AMS_Stack_07_Voltage_Cell_07 : 55|16@0- (1,0) [0|0] "mV" Vector__XXX
 SG_ AMS_Stack_07_Voltage_Cell_06 : 39|16@0- (1,0) [0|0] "mV" Vector__XXX
 SG_ AMS_Stack_07_Voltage_Cell_05 : 23|16@0- (1,0) [0|0] "mV" Vector__XXX
 SG_ AMS_Stack_07_Voltage_Cell_04 : 7|16@0- (1,0) [0|0] "mV" Vector__XXX

BO_ 1394 AMS_Voltages_Stack_07_Cell_8_11: 8 _04_HV_AMS
 SG_ AMS_Stack_07_Voltage_Cell_11 : 55|16@0- (1,0) [0|0] "mV" Vector__XXX
 SG_ AMS_Stack_07_Voltage_Cell_10 : 39|16@0- (1,0) [0|0] "mV" Vector__XXX
 SG_ AMS_Stack_07_Voltage_Cell_09 : 23|16@0- (1,0) [0|0] "mV" Vector__XXX
 SG_ AMS_Stack_07_Voltage_Cell_08 : 7|16@0- (1,0) [0|0] "mV" Vector__XXX

BO_ 1408 AMS_Voltages_Stack_08_Cell_0_3: 8 _04_HV_AMS
 SG_ AMS_Stack_08_Voltage_Cell_03 : 55|16@0- (1,0) [0|0] "mV" Vector__XXX
 SG_ AMS_Stack_08_Voltage_Cell_02 : 39|16@0- (1,0) [0|0] "mV" Vector__XXX
 SG_ AMS_Stack_08_Voltage_Cell_01 : 23|16@0- (1,0) [0|0] "mV" Vector__XXX
 SG_ AMS_Stack_08_Voltage_Cell_00 : 7|16@0- (1,0) [0|0] "mV" Vector__XXX

BO_ 1409 AMS_Voltages_Stack_08_Cell_4_7: 8 _04_HV_AMS
 SG_ AMS_Stack_08_Voltage_Cell_07 : 55|16@0- (1,0) [0|0] "mV" Vector__XXX
 SG_ AMS_Stack_08_Voltage_Cell_06 : 39|16@0- (1,0) [0|0] "mV" Vector__XXX
 SG_ AMS_Stack_08_Voltage_Cell_05 : 23|16@0- (1,0) [0|0] "mV" Vector__XXX
 SG_ AMS_Stack_08_Voltage_Cell_04 : 7|16@0- (1,0) [0|0] "mV" Vector__XXX

BO_ 1410 AMS_Voltages_Stack_08_Cell_8_11: 8 _04_HV_AMS
 SG_ AMS_Stack_08_Voltage_Cell_11 : 55|16@0- (1,0) [0|0] "mV" Vector__XXX
 SG_ AMS_Stack_08_Voltage_Cell_10 : 39|16@0- (1,0) [0|0] "mV" Vector__XXX
 SG_ AMS_Stack_08_Voltage_Cell_09 : 23|16@0- (1,0) [0|0] "mV" Vector__XXX
 SG_ AMS_Stack_08_Voltage_Cell_08 : 7|16@0- (1,0) [0|0] "mV" Vector__XXX

BO_ 1424 AMS_Voltages_Stack_09_Cell_0_3: 8 _04_HV_AMS
 SG_ AMS_Stack_09_Voltage_Cell_03 : 55|16@0- (1,0) [0|0] "mV" Vector__XXX
 SG_ AMS_Stack_09_Voltage_Cell_02 : 39|16@0- (1,0) [0|0] "mV" Vector__XXX
 SG_ AMS_Stack_09_Voltage_Cell_01 : 23|16@0- (1,0) [0|0] "mV" Vector__XXX
 SG_ AMS_Stack_09_Voltage_Cell_00 : 7|16@0- (1,0) [0|0] "mV" Vector__XXX

BO_ 1425 AMS_Voltages_Stack_09_Cell_4_7: 8 _04_HV_AMS
 SG_ AMS_Stack_09_Voltage_Cell_07 : 55|16@0- (1,0) [0|0] "mV" Vector__XXX
 SG_ AMS_Stack_09_Voltage_Cell_06 : 39|16@0- (1,0) [0|0] "mV" Vector__XXX
 SG_ AMS_Stack_09_Voltage_Cell_05 : 23|16@0- (1,0) [0|0] "mV" Vector__XXX
 SG_ AMS_Stack_09_Voltage_Cell_04 : 7|16@0- (1,0) [0|0] "mV" Vector__XXX

BO_ 1426 AMS_Voltages_Stack_09_Cell_8_11: 8 _04_HV_AMS
 SG_ AMS_Stack_09_Voltage_Cell_11 : 55|16@0- (1,0) [0|0] "mV" Vector__XXX
 SG_ AMS_Stack_09_Voltage_Cell_10 : 39|16@0- (1,0) [0|0] "mV" Vector__XXX
 SG_ AMS_Stack_09_Voltage_Cell_09 : 23|16@0- (1,0) [0|0] "mV" Vector__XXX
 SG_ AMS_Stack_09_Voltage_Cell_08 : 7|16@0- (1,0) [0|0] "mV" Vector__XXX

BO_ 1440 AMS_Voltages_Stack_10_Cell_0_3: 8 _04_HV_AMS
 SG_ AMS_Stack_10_Voltage_Cell_03 : 55|16@0- (1,0) [0|0] "mV" Vector__XXX
 SG_ AMS_Stack_10_Voltage_Cell_02 : 39|16@0- (1,0) [0|0] "mV" Vector__XXX
 SG_ AMS_Stack_10_Voltage_Cell_01 : 23|16@0- (1,0) [0|0] "mV" Vector__XXX
 SG_ AMS_Stack_10_Voltage_Cell_00 : 7|16@0- (1,0) [0|0] "mV" Vector__XXX

BO_ 1441 AMS_Voltages_Stack_10_Cell_4_7: 8 _04_HV_AMS
 SG_ AMS_Stack_10_Voltage_Cell_07 : 55|16@0- (1,0) [0|0] "mV" Vector__XXX
 SG_ AMS_Stack_10_Voltage_Cell_06 : 39|16@0- (1,0) [0|0] "mV" Vector__XXX
 SG_ AMS_Stack_10_Voltage_Cell_05 : 23|16@0- (1,0) [0|0] "mV" Vector__XXX
 SG_ AMS_Stack_10_Voltage_Cell_04 : 7|16@0- (1,0) [0|0] "mV" Vector__XXX

BO_ 1442 AMS_Voltages_Stack_10_Cell_8_11: 8 _04_HV_AMS
 SG_ AMS_Stack_10_Voltage_Cell_11 : 55|16@0- (1,0) [0|0] "mV" Vector__XXX
 SG_ AMS_Stack_10_Voltage_Cell_10 : 39|16@0- (1,0) [0|0] "mV" Vector__XXX
 SG_ AMS_Stack_10_Voltage_Cell_09 : 23|16@0- (1,0) [0|0] "mV" Vector__XXX
 SG_ AMS_Stack_10_Voltage_Cell_08 : 7|16@0- (1,0) [0|0] "mV" Vector__XXX

BO_ 1456 AMS_Voltages_Stack_11_Cell_0_3: 8 _04_HV_AMS
 SG_ AMS_Stack_11_Voltage_Cell_03 : 55|16@0- (1,0) [0|0] "mV" Vector__XXX
 SG_ AMS_Stack_11_Voltage_Cell_02 : 39|16@0- (1,0) [0|0] "mV" Vector__XXX
 SG_ AMS_Stack_11_Voltage_Cell_01 : 23|16@0- (1,0) [0|0] "mV" Vector__XXX
 SG_ AMS_Stack_11_Voltage_Cell_00 : 7|16@0- (1,0) [0|0] "mV" Vector__XXX

BO_ 1457 AMS_Voltages_Stack_11_Cell_4_7: 8 _04_HV_AMS
 SG_ AMS_Stack_11_Voltage_Cell_07 : 55|16@0- (1,0) [0|0] "mV" Vector__XXX
 SG_ AMS_Stack_11_Voltage_Cell_06 : 39|16@0- (1,0) [0|0] "mV" Vector__XXX
 SG_ AMS_Stack_11_Voltage_Cell_05 : 23|16@0- (1,0) [0|0] "mV" Vector__XXX
 SG_ AMS_Stack_11_Voltage_Cell_04 : 7|16@0- (1,0) [0|0] "mV" Vector__XXX

BO_ 1458 AMS_Voltages_Stack_11_Cell_8_11: 8 _04_HV_AMS
 SG_ AMS_Stack_11_Voltage_Cell_11 : 55|16@0- (1,0) [0|0] "mV" Vector__XXX
 SG_ AMS_Stack_11_Voltage_Cell_10 : 39|16@0- (1,0) [0|0] "mV" Vector__XXX
 SG_ AMS_Stack_11_Voltage_Cell_09 : 23|16@0- (1,0) [0|0] "mV" Vector__XXX
 SG_ AMS_Stack_11_Voltage_Cell_08 : 7|16@0- (1,0) [0|0] "mV" Vector__XXX

BO_ 1220 Status_AMS_14_Temp_Stack_0_11: 8 _04_HV_AMS
 SG_ AMS_FLT_Temp_Internal_Stack_11 : 55|1@0+ (1,0) [0|0] "" Vector__XXX
 SG_ AMS_FLT_Temp_Internal_Stack_10 : 50|1@0+ (1,0) [0|0] "" Vector__XXX
 SG_ AMS_FLT_Temp_Internal_Stack_09 : 45|1@0+ (1,0) [0|0] "" Vector__XXX
 SG_ AMS_FLT_Temp_Internal_Stack_08 : 40|1@0+ (1,0) [0|0] "" Vector__XXX
 SG_ AMS_FLT_Temp_Internal_Stack_07 : 35|1@0+ (1,0) [0|0] "" Vector__XXX
 SG_ AMS_FLT_Temp_Internal_Stack_06 : 30|1@0+ (1,0) [0|0] "" Vector__XXX
 SG_ AMS_FLT_Temp_Internal_Stack_05 : 25|1@0+ (1,0) [0|0] "" Vector__XXX
 SG_ AMS_FLT_Temp_Internal_Stack_04 : 20|1@0+ (1,0) [0|0] "" Vector__XXX
 SG_ AMS_FLT_Temp_Internal_Stack_03 : 15|1@0+ (1,0) [0|0] "" Vector__XXX
 SG_ AMS_FLT_Temp_Internal_Stack_02 : 10|1@0+ (1,0) [0|0] "" Vector__XXX
 SG_ AMS_FLT_Temp_Internal_Stack_01 : 5|1@0+ (1,0) [0|0] "" Vector__XXX
 SG_ AMS_FLT_Temp_Internal_Stack_00 : 0|1@0+ (1,0) [0|0] "" Vector__XXX
 SG_ AMS_FLT_Cell_Temp_3_Stack_11 : 59|1@0+ (1,0) [0|0] "" Vector__XXX
 SG_ AMS_FLT_Cell_Temp_3_Stack_10 : 54|1@0+ (1,0) [0|0] "" Vector__XXX
 SG_ AMS_FLT_Cell_Temp_3_Stack_09 : 49|1@0+ (1,0) [0|0] "" Vector__XXX
 SG_ AMS_FLT_Cell_Temp_3_Stack_08 : 44|1@0+ (1,0) [0|0] "" Vector__XXX
 SG_ AMS_FLT_Cell_Temp_3_Stack_07 : 39|1@0+ (1,0) [0|0] "" Vector__XXX
 SG_ AMS_FLT_Cell_Temp_3_Stack_06 : 34|1@0+ (1,0) [0|0] "" Vector__XXX
 SG_ AMS_FLT_Cell_Temp_3_Stack_05 : 29|1@0+ (1,0) [0|0] "" Vector__XXX
 SG_ AMS_FLT_Cell_Temp_3_Stack_04 : 24|1@0+ (1,0) [0|0] "" Vector__XXX
 SG_ AMS_FLT_Cell_Temp_3_Stack_03 : 19|1@0+ (1,0) [0|0] "" Vector__XXX
 SG_ AMS_FLT_Cell_Temp_3_Stack_02 : 14|1@0+ (1,0) [0|0] "" Vector__XXX
 SG_ AMS_FLT_Cell_Temp_3_Stack_01 : 9|1@0+ (1,0) [0|0] "" Vector__XXX
 SG_ AMS_FLT_Cell_Temp_3_Stack_00 : 4|1@0+ (1,0) [0|0] "" Vector__XXX
 SG_ AMS_FLT_Cell_Temp_2_Stack_11 : 58|1@0+ (1,0) [0|0] "" Vector__XXX
 SG_ AMS_FLT_Cell_Temp_2_Stack_10 : 53|1@0+ (1,0) [0|0] "" Vector__XXX
 SG_ AMS_FLT_Cell_Temp_2_Stack_09 : 48|1@0+ (1,0) [0|0] "" Vector__XXX
 SG_ AMS_FLT_Cell_Temp_2_Stack_08 : 43|1@0+ (1,0) [0|0] "" Vector__XXX
 SG_ AMS_FLT_Cell_Temp_2_Stack_07 : 38|1@0+ (1,0) [0|0] "" Vector__XXX
 SG_ AMS_FLT_Cell_Temp_2_Stack_06 : 33|1@0+ (1,0) [0|0] "" Vector__XXX
 SG_ AMS_FLT_Cell_Temp_2_Stack_05 : 28|1@0+ (1,0) [0|0] "" Vector__XXX
 SG_ AMS_FLT_Cell_Temp_2_Stack_04 : 23|1@0+ (1,0) [0|0] "" Vector__XXX
 SG_ AMS_FLT_Cell_Temp_2_Stack_03 : 18|1@0+ (1,0) [0|0] "" Vector__XXX
 SG_ AMS_FLT_Cell_Temp_2_Stack_02 : 13|1@0+ (1,0) [0|0] "" Vector__XXX
 SG_ AMS_FLT_Cell_Temp_2_Stack_01 : 8|1@0+ (1,0) [0|0] "" Vector__XXX
 SG_ AMS_FLT_Cell_Temp_2_Stack_00 : 3|1@0+ (1,0) [0|0] "" Vector__XXX
 SG_ AMS_FLT_Cell_Temp_1_Stack_11 : 57|1@0+ (1,0) [0|0] "" Vector__XXX
 SG_ AMS_FLT_Cell_Temp_1_Stack_10 : 52|1@0+ (1,0) [0|0] "" Vector__XXX
 SG_ AMS_FLT_Cell_Temp_1_Stack_09 : 47|1@0+ (1,0) [0|0] "" Vector__XXX
 SG_ AMS_FLT_Cell_Temp_1_Stack_08 : 42|1@0+ (1,0) [0|0] "" Vector__XXX
 SG_ AMS_FLT_Cell_Temp_1_Stack_07 : 37|1@0+ (1,0) [0|0] "" Vector__XXX
 SG_ AMS_FLT_Cell_Temp_1_Stack_06 : 32|1@0+ (1,0) [0|0] "" Vector__XXX
 SG_ AMS_FLT_Cell_Temp_1_Stack_05 : 27|1@0+ (1,0) [0|0] "" Vector__XXX
 SG_ AMS_FLT_Cell_Temp_1_Stack_04 : 22|1@0+ (1,0) [0|0] "" Vector__XXX
 SG_ AMS_FLT_Cell_Temp_1_Stack_03 : 17|1@0+ (1,0) [0|0] "" Vector__XXX
 SG_ AMS_FLT_Cell_Temp_1_Stack_02 : 12|1@0+ (1,0) [0|0] "" Vector__XXX
 SG_ AMS_FLT_Cell_Temp_1_Stack_01 : 7|1@0+ (1,0) [0|0] "" Vector__XXX
 SG_ AMS_FLT_Cell_Temp_1_Stack_00 : 2|1@0+ (1,0) [0|0] "" Vector__XXX
 SG_ AMS_FLT_Cell_Temp_0_Stack_11 : 56|1@0+ (1,0) [0|0] "" Vector__XXX
 SG_ AMS_FLT_Cell_Temp_0_Stack_10 : 51|1@0+ (1,0) [0|0] "" Vector__XXX
 SG_ AMS_FLT_Cell_Temp_0_Stack_09 : 46|1@0+ (1,0) [0|0] "" Vector__XXX
 SG_ AMS_FLT_Cell_Temp_0_Stack_08 : 41|1@0+ (1,0) [0|0] "" Vector__XXX
 SG_ AMS_FLT_Cell_Temp_0_Stack_07 : 36|1@0+ (1,0) [0|0] "" Vector__XXX
 SG_ AMS_FLT_Cell_Temp_0_Stack_06 : 31|1@0+ (1,0) [0|0] "" Vector__XXX
 SG_ AMS_FLT_Cell_Temp_0_Stack_05 : 26|1@0+ (1,0) [0|0] "" Vector__XXX
 SG_ AMS_FLT_Cell_Temp_0_Stack_04 : 21|1@0+ (1,0) [0|0] "" Vector__XXX
 SG_ AMS_FLT_Cell_Temp_0_Stack_03 : 16|1@0+ (1,0) [0|0] "" Vector__XXX
 SG_ AMS_FLT_Cell_Temp_0_Stack_02 : 11|1@0+ (1,0) [0|0] "" Vector__XXX
 SG_ AMS_FLT_Cell_Temp_0_Stack_01 : 6|1@0+ (1,0) [0|0] "" Vector__XXX
 SG_ AMS_FLT_Cell_Temp_0_Stack_00 : 1|1@0+ (1,0) [0|0] "" Vector__XXX

BO_ 1204 Status_AMS_13_OW_Stack_8_11: 6 _04_HV_AMS
 SG_ AMS_FLT_OW_Stack_11_C11 : 47|1@0+ (1,0) [0|0] "" Vector__XXX
 SG_ AMS_FLT_OW_Stack_11_C10 : 46|1@0+ (1,0) [0|0] "" Vector__XXX
 SG_ AMS_FLT_OW_Stack_11_C09 : 45|1@0+ (1,0) [0|0] "" Vector__XXX
 SG_ AMS_FLT_OW_Stack_11_C08 : 44|1@0+ (1,0) [0|0] "" Vector__XXX
 SG_ AMS_FLT_OW_Stack_11_C07 : 43|1@0+ (1,0) [0|0] "" Vector__XXX
 SG_ AMS_FLT_OW_Stack_11_C06 : 42|1@0+ (1,0) [0|0] "" Vector__XXX
 SG_ AMS_FLT_OW_Stack_11_C05 : 41|1@0+ (1,0) [0|0] "" Vector__XXX
 SG_ AMS_FLT_OW_Stack_11_C04 : 40|1@0+ (1,0) [0|0] "" Vector__XXX
 SG_ AMS_FLT_OW_Stack_11_C03 : 39|1@0+ (1,0) [0|0] "" Vector__XXX
 SG_ AMS_FLT_OW_Stack_11_C02 : 38|1@0+ (1,0) [0|0] "" Vector__XXX
 SG_ AMS_FLT_OW_Stack_11_C01 : 37|1@0+ (1,0) [0|0] "" Vector__XXX
 SG_ AMS_FLT_OW_Stack_11_C00 : 36|1@0+ (1,0) [0|0] "" Vector__XXX
 SG_ AMS_FLT_OW_Stack_10_C11 : 35|1@0+ (1,0) [0|0] "" Vector__XXX
 SG_ AMS_FLT_OW_Stack_10_C10 : 34|1@0+ (1,0) [0|0] "" Vector__XXX
 SG_ AMS_FLT_OW_Stack_10_C09 : 33|1@0+ (1,0) [0|0] "" Vector__XXX
 SG_ AMS_FLT_OW_Stack_10_C08 : 32|1@0+ (1,0) [0|0] "" Vector__XXX
 SG_ AMS_FLT_OW_Stack_10_C07 : 31|1@0+ (1,0) [0|0] "" Vector__XXX
 SG_ AMS_FLT_OW_Stack_10_C06 : 30|1@0+ (1,0) [0|0] "" Vector__XXX
 SG_ AMS_FLT_OW_Stack_10_C05 : 29|1@0+ (1,0) [0|0] "" Vector__XXX
 SG_ AMS_FLT_OW_Stack_10_C04 : 28|1@0+ (1,0) [0|0] "" Vector__XXX
 SG_ AMS_FLT_OW_Stack_10_C03 : 27|1@0+ (1,0) [0|0] "" Vector__XXX
 SG_ AMS_FLT_OW_Stack_10_C02 : 26|1@0+ (1,0) [0|0] "" Vector__XXX
 SG_ AMS_FLT_OW_Stack_10_C01 : 25|1@0+ (1,0) [0|0] "" Vector__XXX
 SG_ AMS_FLT_OW_Stack_10_C00 : 24|1@0+ (1,0) [0|0] "" Vector__XXX
 SG_ AMS_FLT_OW_Stack_09_C11 : 23|1@0+ (1,0) [0|0] "" Vector__XXX
 SG_ AMS_FLT_OW_Stack_09_C10 : 22|1@0+ (1,0) [0|0] "" Vector__XXX
 SG_ AMS_FLT_OW_Stack_09_C09 : 21|1@0+ (1,0) [0|0] "" Vector__XXX
 SG_ AMS_FLT_OW_Stack_09_C08 : 20|1@0+ (1,0) [0|0] "" Vector__XXX
 SG_ AMS_FLT_OW_Stack_09_C07 : 19|1@0+ (1,0) [0|0] "" Vector__XXX
 SG_ AMS_FLT_OW_Stack_09_C06 : 18|1@0+ (1,0) [0|0] "" Vector__XXX
 SG_ AMS_FLT_OW_Stack_09_C05 : 17|1@0+ (1,0) [0|0] "" Vector__XXX
 SG_ AMS_FLT_OW_Stack_09_C04 : 16|1@0+ (1,0) [0|0] "" Vector__XXX
 SG_ AMS_FLT_OW_Stack_09_C03 : 15|1@0+ (1,0) [0|0] "" Vector__XXX
 SG_ AMS_FLT_OW_Stack_09_C02 : 14|1@0+ (1,0) [0|0] "" Vector__XXX
 SG_ AMS_FLT_OW_Stack_09_C01 : 13|1@0+ (1,0) [0|0] "" Vector__XXX
 SG_ AMS_FLT_OW_Stack_09_C00 : 12|1@0+ (1,0) [0|0] "" Vector__XXX
 SG_ AMS_FLT_OW_Stack_08_C11 : 11|1@0+ (1,0) [0|0] "" Vector__XXX
 SG_ AMS_FLT_OW_Stack_08_C10 : 10|1@0+ (1,0) [0|0] "" Vector__XXX
 SG_ AMS_FLT_OW_Stack_08_C09 : 9|1@0+ (1,0) [0|0] "" Vector__XXX
 SG_ AMS_FLT_OW_Stack_08_C08 : 8|1@0+ (1,0) [0|0] "" Vector__XXX
 SG_ AMS_FLT_OW_Stack_08_C07 : 7|1@0+ (1,0) [0|0] "" Vector__XXX
 SG_ AMS_FLT_OW_Stack_08_C06 : 6|1@0+ (1,0) [0|0] "" Vector__XXX
 SG_ AMS_FLT_OW_Stack_08_C05 : 5|1@0+ (1,0) [0|0] "" Vector__XXX
 SG_ AMS_FLT_OW_Stack_08_C04 : 4|1@0+ (1,0) [0|0] "" Vector__XXX
 SG_ AMS_FLT_OW_Stack_08_C03 : 3|1@0+ (1,0) [0|0] "" Vector__XXX
 SG_ AMS_FLT_OW_Stack_08_C02 : 2|1@0+ (1,0) [0|0] "" Vector__XXX
 SG_ AMS_FLT_OW_Stack_08_C01 : 1|1@0+ (1,0) [0|0] "" Vector__XXX
 SG_ AMS_FLT_OW_Stack_08_C00 : 0|1@0+ (1,0) [0|0] "" Vector__XXX

BO_ 1188 Status_AMS_12_OW_Stack_4_7: 6 _04_HV_AMS
 SG_ AMS_FLT_OW_Stack_07_C11 : 47|1@0+ (1,0) [0|0] "" Vector__XXX
 SG_ AMS_FLT_OW_Stack_07_C10 : 46|1@0+ (1,0) [0|0] "" Vector__XXX
 SG_ AMS_FLT_OW_Stack_07_C09 : 45|1@0+ (1,0) [0|0] "" Vector__XXX
 SG_ AMS_FLT_OW_Stack_07_C08 : 44|1@0+ (1,0) [0|0] "" Vector__XXX
 SG_ AMS_FLT_OW_Stack_07_C07 : 43|1@0+ (1,0) [0|0] "" Vector__XXX
 SG_ AMS_FLT_OW_Stack_07_C06 : 42|1@0+ (1,0) [0|0] "" Vector__XXX
 SG_ AMS_FLT_OW_Stack_07_C05 : 41|1@0+ (1,0) [0|0] "" Vector__XXX
 SG_ AMS_FLT_OW_Stack_07_C04 : 40|1@0+ (1,0) [0|0] "" Vector__XXX
 SG_ AMS_FLT_OW_Stack_07_C03 : 39|1@0+ (1,0) [0|0] "" Vector__XXX
 SG_ AMS_FLT_OW_Stack_07_C02 : 38|1@0+ (1,0) [0|0] "" Vector__XXX
 SG_ AMS_FLT_OW_Stack_07_C01 : 37|1@0+ (1,0) [0|0] "" Vector__XXX
 SG_ AMS_FLT_OW_Stack_07_C00 : 36|1@0+ (1,0) [0|0] "" Vector__XXX
 SG_ AMS_FLT_OW_Stack_06_C11 : 35|1@0+ (1,0) [0|0] "" Vector__XXX
 SG_ AMS_FLT_OW_Stack_06_C10 : 34|1@0+ (1,0) [0|0] "" Vector__XXX
 SG_ AMS_FLT_OW_Stack_06_C09 : 33|1@0+ (1,0) [0|0] "" Vector__XXX
 SG_ AMS_FLT_OW_Stack_06_C08 : 32|1@0+ (1,0) [0|0] "" Vector__XXX
 SG_ AMS_FLT_OW_Stack_06_C07 : 31|1@0+ (1,0) [0|0] "" Vector__XXX
 SG_ AMS_FLT_OW_Stack_06_C06 : 30|1@0+ (1,0) [0|0] "" Vector__XXX
 SG_ AMS_FLT_OW_Stack_06_C05 : 29|1@0+ (1,0) [0|0] "" Vector__XXX
 SG_ AMS_FLT_OW_Stack_06_C04 : 28|1@0+ (1,0) [0|0] "" Vector__XXX
 SG_ AMS_FLT_OW_Stack_06_C03 : 27|1@0+ (1,0) [0|0] "" Vector__XXX
 SG_ AMS_FLT_OW_Stack_06_C02 : 26|1@0+ (1,0) [0|0] "" Vector__XXX
 SG_ AMS_FLT_OW_Stack_06_C01 : 25|1@0+ (1,0) [0|0] "" Vector__XXX
 SG_ AMS_FLT_OW_Stack_06_C00 : 24|1@0+ (1,0) [0|0] "" Vector__XXX
 SG_ AMS_FLT_OW_Stack_05_C11 : 23|1@0+ (1,0) [0|0] "" Vector__XXX
 SG_ AMS_FLT_OW_Stack_05_C10 : 22|1@0+ (1,0) [0|0] "" Vector__XXX
 SG_ AMS_FLT_OW_Stack_05_C09 : 21|1@0+ (1,0) [0|0] "" Vector__XXX
 SG_ AMS_FLT_OW_Stack_05_C08 : 20|1@0+ (1,0) [0|0] "" Vector__XXX
 SG_ AMS_FLT_OW_Stack_05_C07 : 19|1@0+ (1,0) [0|0] "" Vector__XXX
 SG_ AMS_FLT_OW_Stack_05_C06 : 18|1@0+ (1,0) [0|0] "" Vector__XXX
 SG_ AMS_FLT_OW_Stack_05_C05 : 17|1@0+ (1,0) [0|0] "" Vector__XXX
 SG_ AMS_FLT_OW_Stack_05_C04 : 16|1@0+ (1,0) [0|0] "" Vector__XXX
 SG_ AMS_FLT_OW_Stack_05_C03 : 15|1@0+ (1,0) [0|0] "" Vector__XXX
 SG_ AMS_FLT_OW_Stack_05_C02 : 14|1@0+ (1,0) [0|0] "" Vector__XXX
 SG_ AMS_FLT_OW_Stack_05_C01 : 13|1@0+ (1,0) [0|0] "" Vector__XXX
 SG_ AMS_FLT_OW_Stack_05_C00 : 12|1@0+ (1,0) [0|0] "" Vector__XXX
 SG_ AMS_FLT_OW_Stack_04_C11 : 11|1@0+ (1,0) [0|0] "" Vector__XXX
 SG_ AMS_FLT_OW_Stack_04_C10 : 10|1@0+ (1,0) [0|0] "" Vector__XXX
 SG_ AMS_FLT_OW_Stack_04_C09 : 9|1@0+ (1,0) [0|0] "" Vector__XXX
 SG_ AMS_FLT_OW_Stack_04_C08 : 8|1@0+ (1,0) [0|0] "" Vector__XXX
 SG_ AMS_FLT_OW_Stack_04_C07 : 7|1@0+ (1,0) [0|0] "" Vector__XXX
 SG_ AMS_FLT_OW_Stack_04_C06 : 6|1@0+ (1,0) [0|0] "" Vector__XXX
 SG_ AMS_FLT_OW_Stack_04_C05 : 5|1@0+ (1,0) [0|0] "" Vector__XXX
 SG_ AMS_FLT_OW_Stack_04_C04 : 4|1@0+ (1,0) [0|0] "" Vector__XXX
 SG_ AMS_FLT_OW_Stack_04_C03 : 3|1@0+ (1,0) [0|0] "" Vector__XXX
 SG_ AMS_FLT_OW_Stack_04_C02 : 2|1@0+ (1,0) [0|0] "" Vector__XXX
 SG_ AMS_FLT_OW_Stack_04_C01 : 1|1@0+ (1,0) [0|0] "" Vector__XXX
 SG_ AMS_FLT_OW_Stack_04_C00 : 0|1@0+ (1,0) [0|0] "" Vector__XXX

BO_ 1172 Status_AMS_11_OW_Stack_0_3: 6 _04_HV_AMS
 SG_ AMS_FLT_OW_Stack_03_C11 : 47|1@0+ (1,0) [0|0] "" Vector__XXX
 SG_ AMS_FLT_OW_Stack_03_C10 : 46|1@0+ (1,0) [0|0] "" Vector__XXX
 SG_ AMS_FLT_OW_Stack_03_C09 : 45|1@0+ (1,0) [0|0] "" Vector__XXX
 SG_ AMS_FLT_OW_Stack_03_C08 : 44|1@0+ (1,0) [0|0] "" Vector__XXX
 SG_ AMS_FLT_OW_Stack_03_C07 : 43|1@0+ (1,0) [0|0] "" Vector__XXX
 SG_ AMS_FLT_OW_Stack_03_C06 : 42|1@0+ (1,0) [0|0] "" Vector__XXX
 SG_ AMS_FLT_OW_Stack_03_C05 : 41|1@0+ (1,0) [0|0] "" Vector__XXX
 SG_ AMS_FLT_OW_Stack_03_C04 : 40|1@0+ (1,0) [0|0] "" Vector__XXX
 SG_ AMS_FLT_OW_Stack_03_C03 : 39|1@0+ (1,0) [0|0] "" Vector__XXX
 SG_ AMS_FLT_OW_Stack_03_C02 : 38|1@0+ (1,0) [0|0] "" Vector__XXX
 SG_ AMS_FLT_OW_Stack_03_C01 : 37|1@0+ (1,0) [0|0] "" Vector__XXX
 SG_ AMS_FLT_OW_Stack_03_C00 : 36|1@0+ (1,0) [0|0] "" Vector__XXX
 SG_ AMS_FLT_OW_Stack_02_C11 : 35|1@0+ (1,0) [0|0] "" Vector__XXX
 SG_ AMS_FLT_OW_Stack_02_C10 : 34|1@0+ (1,0) [0|0] "" Vector__XXX
 SG_ AMS_FLT_OW_Stack_02_C09 : 33|1@0+ (1,0) [0|0] "" Vector__XXX
 SG_ AMS_FLT_OW_Stack_02_C08 : 32|1@0+ (1,0) [0|0] "" Vector__XXX
 SG_ AMS_FLT_OW_Stack_02_C07 : 31|1@0+ (1,0) [0|0] "" Vector__XXX
 SG_ AMS_FLT_OW_Stack_02_C06 : 30|1@0+ (1,0) [0|0] "" Vector__XXX
 SG_ AMS_FLT_OW_Stack_02_C05 : 29|1@0+ (1,0) [0|0] "" Vector__XXX
 SG_ AMS_FLT_OW_Stack_02_C04 : 28|1@0+ (1,0) [0|0] "" Vector__XXX
 SG_ AMS_FLT_OW_Stack_02_C03 : 27|1@0+ (1,0) [0|0] "" Vector__XXX
 SG_ AMS_FLT_OW_Stack_02_C02 : 26|1@0+ (1,0) [0|0] "" Vector__XXX
 SG_ AMS_FLT_OW_Stack_02_C01 : 25|1@0+ (1,0) [0|0] "" Vector__XXX
 SG_ AMS_FLT_OW_Stack_02_C00 : 24|1@0+ (1,0) [0|0] "" Vector__XXX
 SG_ AMS_FLT_OW_Stack_01_C11 : 23|1@0+ (1,0) [0|0] "" Vector__XXX
 SG_ AMS_FLT_OW_Stack_01_C10 : 22|1@0+ (1,0) [0|0] "" Vector__XXX
 SG_ AMS_FLT_OW_Stack_01_C09 : 21|1@0+ (1,0) [0|0] "" Vector__XXX
 SG_ AMS_FLT_OW_Stack_01_C08 : 20|1@0+ (1,0) [0|0] "" Vector__XXX
 SG_ AMS_FLT_OW_Stack_01_C07 : 19|1@0+ (1,0) [0|0] "" Vector__XXX
 SG_ AMS_FLT_OW_Stack_01_C06 : 18|1@0+ (1,0) [0|0] "" Vector__XXX
 SG_ AMS_FLT_OW_Stack_01_C05 : 17|1@0+ (1,0) [0|0] "" Vector__XXX
 SG_ AMS_FLT_OW_Stack_01_C04 : 16|1@0+ (1,0) [0|0] "" Vector__XXX
 SG_ AMS_FLT_OW_Stack_01_C03 : 15|1@0+ (1,0) [0|0] "" Vector__XXX
 SG_ AMS_FLT_OW_Stack_01_C02 : 14|1@0+ (1,0) [0|0] "" Vector__XXX
 SG_ AMS_FLT_OW_Stack_01_C01 : 13|1@0+ (1,0) [0|0] "" Vector__XXX
 SG_ AMS_FLT_OW_Stack_01_C00 : 12|1@0+ (1,0) [0|0] "" Vector__XXX
 SG_ AMS_FLT_OW_Stack_00_C11 : 11|1@0+ (1,0) [0|0] "" Vector__XXX
 SG_ AMS_FLT_OW_Stack_00_C10 : 10|1@0+ (1,0) [0|0] "" Vector__XXX
 SG_ AMS_FLT_OW_Stack_00_C09 : 9|1@0+ (1,0) [0|0] "" Vector__XXX
 SG_ AMS_FLT_OW_Stack_00_C08 : 8|1@0+ (1,0) [0|0] "" Vector__XXX
 SG_ AMS_FLT_OW_Stack_00_C07 : 7|1@0+ (1,0) [0|0] "" Vector__XXX
 SG_ AMS_FLT_OW_Stack_00_C06 : 6|1@0+ (1,0) [0|0] "" Vector__XXX
 SG_ AMS_FLT_OW_Stack_00_C05 : 5|1@0+ (1,0) [0|0] "" Vector__XXX
 SG_ AMS_FLT_OW_Stack_00_C04 : 4|1@0+ (1,0) [0|0] "" Vector__XXX
 SG_ AMS_FLT_OW_Stack_00_C03 : 3|1@0+ (1,0) [0|0] "" Vector__XXX
 SG_ AMS_FLT_OW_Stack_00_C02 : 2|1@0+ (1,0) [0|0] "" Vector__XXX
 SG_ AMS_FLT_OW_Stack_00_C01 : 1|1@0+ (1,0) [0|0] "" Vector__XXX
 SG_ AMS_FLT_OW_Stack_00_C00 : 0|1@0+ (1,0) [0|0] "" Vector__XXX

BO_ 1156 Status_AMS_10_UV_Stack_8_11: 6 _04_HV_AMS
 SG_ AMS_FLT_UV_Stack_11_C11 : 47|1@0+ (1,0) [0|0] "" Vector__XXX
 SG_ AMS_FLT_UV_Stack_11_C10 : 46|1@0+ (1,0) [0|0] "" Vector__XXX
 SG_ AMS_FLT_UV_Stack_11_C09 : 45|1@0+ (1,0) [0|0] "" Vector__XXX
 SG_ AMS_FLT_UV_Stack_11_C08 : 44|1@0+ (1,0) [0|0] "" Vector__XXX
 SG_ AMS_FLT_UV_Stack_11_C07 : 43|1@0+ (1,0) [0|0] "" Vector__XXX
 SG_ AMS_FLT_UV_Stack_11_C06 : 42|1@0+ (1,0) [0|0] "" Vector__XXX
 SG_ AMS_FLT_UV_Stack_11_C05 : 41|1@0+ (1,0) [0|0] "" Vector__XXX
 SG_ AMS_FLT_UV_Stack_11_C04 : 40|1@0+ (1,0) [0|0] "" Vector__XXX
 SG_ AMS_FLT_UV_Stack_11_C03 : 39|1@0+ (1,0) [0|0] "" Vector__XXX
 SG_ AMS_FLT_UV_Stack_11_C02 : 38|1@0+ (1,0) [0|0] "" Vector__XXX
 SG_ AMS_FLT_UV_Stack_11_C01 : 37|1@0+ (1,0) [0|0] "" Vector__XXX
 SG_ AMS_FLT_UV_Stack_11_C00 : 36|1@0+ (1,0) [0|0] "" Vector__XXX
 SG_ AMS_FLT_UV_Stack_10_C11 : 35|1@0+ (1,0) [0|0] "" Vector__XXX
 SG_ AMS_FLT_UV_Stack_10_C10 : 34|1@0+ (1,0) [0|0] "" Vector__XXX
 SG_ AMS_FLT_UV_Stack_10_C09 : 33|1@0+ (1,0) [0|0] "" Vector__XXX
 SG_ AMS_FLT_UV_Stack_10_C08 : 32|1@0+ (1,0) [0|0] "" Vector__XXX
 SG_ AMS_FLT_UV_Stack_10_C07 : 31|1@0+ (1,0) [0|0] "" Vector__XXX
 SG_ AMS_FLT_UV_Stack_10_C06 : 30|1@0+ (1,0) [0|0] "" Vector__XXX
 SG_ AMS_FLT_UV_Stack_10_C05 : 29|1@0+ (1,0) [0|0] "" Vector__XXX
 SG_ AMS_FLT_UV_Stack_10_C04 : 28|1@0+ (1,0) [0|0] "" Vector__XXX
 SG_ AMS_FLT_UV_Stack_10_C03 : 27|1@0+ (1,0) [0|0] "" Vector__XXX
 SG_ AMS_FLT_UV_Stack_10_C02 : 26|1@0+ (1,0) [0|0] "" Vector__XXX
 SG_ AMS_FLT_UV_Stack_10_C01 : 25|1@0+ (1,0) [0|0] "" Vector__XXX
 SG_ AMS_FLT_UV_Stack_10_C00 : 24|1@0+ (1,0) [0|0] "" Vector__XXX
 SG_ AMS_FLT_UV_Stack_09_C11 : 23|1@0+ (1,0) [0|0] "" Vector__XXX
 SG_ AMS_FLT_UV_Stack_09_C10 : 22|1@0+ (1,0) [0|0] "" Vector__XXX
 SG_ AMS_FLT_UV_Stack_09_C09 : 21|1@0+ (1,0) [0|0] "" Vector__XXX
 SG_ AMS_FLT_UV_Stack_09_C08 : 20|1@0+ (1,0) [0|0] "" Vector__XXX
 SG_ AMS_FLT_UV_Stack_09_C07 : 19|1@0+ (1,0) [0|0] "" Vector__XXX
 SG_ AMS_FLT_UV_Stack_09_C06 : 18|1@0+ (1,0) [0|0] "" Vector__XXX
 SG_ AMS_FLT_UV_Stack_09_C05 : 17|1@0+ (1,0) [0|0] "" Vector__XXX
 SG_ AMS_FLT_UV_Stack_09_C04 : 16|1@0+ (1,0) [0|0] "" Vector__XXX
 SG_ AMS_FLT_UV_Stack_09_C03 : 15|1@0+ (1,0) [0|0] "" Vector__XXX
 SG_ AMS_FLT_UV_Stack_09_C02 : 14|1@0+ (1,0) [0|0] "" Vector__XXX
 SG_ AMS_FLT_UV_Stack_09_C01 : 13|1@0+ (1,0) [0|0] "" Vector__XXX
 SG_ AMS_FLT_UV_Stack_09_C00 : 12|1@0+ (1,0) [0|0] "" Vector__XXX
 SG_ AMS_FLT_UV_Stack_08_C11 : 11|1@0+ (1,0) [0|0] "" Vector__XXX
 SG_ AMS_FLT_UV_Stack_08_C10 : 10|1@0+ (1,0) [0|0] "" Vector__XXX
 SG_ AMS_FLT_UV_Stack_08_C09 : 9|1@0+ (1,0) [0|0] "" Vector__XXX
 SG_ AMS_FLT_UV_Stack_08_C08 : 8|1@0+ (1,0) [0|0] "" Vector__XXX
 SG_ AMS_FLT_UV_Stack_08_C07 : 7|1@0+ (1,0) [0|0] "" Vector__XXX
 SG_ AMS_FLT_UV_Stack_08_C06 : 6|1@0+ (1,0) [0|0] "" Vector__XXX
 SG_ AMS_FLT_UV_Stack_08_C05 : 5|1@0+ (1,0) [0|0] "" Vector__XXX
 SG_ AMS_FLT_UV_Stack_08_C04 : 4|1@0+ (1,0) [0|0] "" Vector__XXX
 SG_ AMS_FLT_UV_Stack_08_C03 : 3|1@0+ (1,0) [0|0] "" Vector__XXX
 SG_ AMS_FLT_UV_Stack_08_C02 : 2|1@0+ (1,0) [0|0] "" Vector__XXX
 SG_ AMS_FLT_UV_Stack_08_C01 : 1|1@0+ (1,0) [0|0] "" Vector__XXX
 SG_ AMS_FLT_UV_Stack_08_C00 : 0|1@0+ (1,0) [0|0] "" Vector__XXX

BO_ 1140 Status_AMS_09_UV_Stack_4_7: 6 _04_HV_AMS
 SG_ AMS_FLT_UV_Stack_07_C11 : 47|1@0+ (1,0) [0|0] "" Vector__XXX
 SG_ AMS_FLT_UV_Stack_07_C10 : 46|1@0+ (1,0) [0|0] "" Vector__XXX
 SG_ AMS_FLT_UV_Stack_07_C09 : 45|1@0+ (1,0) [0|0] "" Vector__XXX
 SG_ AMS_FLT_UV_Stack_07_C08 : 44|1@0+ (1,0) [0|0] "" Vector__XXX
 SG_ AMS_FLT_UV_Stack_07_C07 : 43|1@0+ (1,0) [0|0] "" Vector__XXX
 SG_ AMS_FLT_UV_Stack_07_C06 : 42|1@0+ (1,0) [0|0] "" Vector__XXX
 SG_ AMS_FLT_UV_Stack_07_C05 : 41|1@0+ (1,0) [0|0] "" Vector__XXX
 SG_ AMS_FLT_UV_Stack_07_C04 : 40|1@0+ (1,0) [0|0] "" Vector__XXX
 SG_ AMS_FLT_UV_Stack_07_C03 : 39|1@0+ (1,0) [0|0] "" Vector__XXX
 SG_ AMS_FLT_UV_Stack_07_C02 : 38|1@0+ (1,0) [0|0] "" Vector__XXX
 SG_ AMS_FLT_UV_Stack_07_C01 : 37|1@0+ (1,0) [0|0] "" Vector__XXX
 SG_ AMS_FLT_UV_Stack_07_C00 : 36|1@0+ (1,0) [0|0] "" Vector__XXX
 SG_ AMS_FLT_UV_Stack_06_C11 : 35|1@0+ (1,0) [0|0] "" Vector__XXX
 SG_ AMS_FLT_UV_Stack_06_C10 : 34|1@0+ (1,0) [0|0] "" Vector__XXX
 SG_ AMS_FLT_UV_Stack_06_C09 : 33|1@0+ (1,0) [0|0] "" Vector__XXX
 SG_ AMS_FLT_UV_Stack_06_C08 : 32|1@0+ (1,0) [0|0] "" Vector__XXX
 SG_ AMS_FLT_UV_Stack_06_C07 : 31|1@0+ (1,0) [0|0] "" Vector__XXX
 SG_ AMS_FLT_UV_Stack_06_C06 : 30|1@0+ (1,0) [0|0] "" Vector__XXX
 SG_ AMS_FLT_UV_Stack_06_C05 : 29|1@0+ (1,0) [0|0] "" Vector__XXX
 SG_ AMS_FLT_UV_Stack_06_C04 : 28|1@0+ (1,0) [0|0] "" Vector__XXX
 SG_ AMS_FLT_UV_Stack_06_C03 : 27|1@0+ (1,0) [0|0] "" Vector__XXX
 SG_ AMS_FLT_UV_Stack_06_C02 : 26|1@0+ (1,0) [0|0] "" Vector__XXX
 SG_ AMS_FLT_UV_Stack_06_C01 : 25|1@0+ (1,0) [0|0] "" Vector__XXX
 SG_ AMS_FLT_UV_Stack_06_C00 : 24|1@0+ (1,0) [0|0] "" Vector__XXX
 SG_ AMS_FLT_UV_Stack_05_C11 : 23|1@0+ (1,0) [0|0] "" Vector__XXX
 SG_ AMS_FLT_UV_Stack_05_C10 : 22|1@0+ (1,0) [0|0] "" Vector__XXX
 SG_ AMS_FLT_UV_Stack_05_C09 : 21|1@0+ (1,0) [0|0] "" Vector__XXX
 SG_ AMS_FLT_UV_Stack_05_C08 : 20|1@0+ (1,0) [0|0] "" Vector__XXX
 SG_ AMS_FLT_UV_Stack_05_C07 : 19|1@0+ (1,0) [0|0] "" Vector__XXX
 SG_ AMS_FLT_UV_Stack_05_C06 : 18|1@0+ (1,0) [0|0] "" Vector__XXX
 SG_ AMS_FLT_UV_Stack_05_C05 : 17|1@0+ (1,0) [0|0] "" Vector__XXX
 SG_ AMS_FLT_UV_Stack_05_C04 : 16|1@0+ (1,0) [0|0] "" Vector__XXX
 SG_ AMS_FLT_UV_Stack_05_C03 : 15|1@0+ (1,0) [0|0] "" Vector__XXX
 SG_ AMS_FLT_UV_Stack_05_C02 : 14|1@0+ (1,0) [0|0] "" Vector__XXX
 SG_ AMS_FLT_UV_Stack_05_C01 : 13|1@0+ (1,0) [0|0] "" Vector__XXX
 SG_ AMS_FLT_UV_Stack_05_C00 : 12|1@0+ (1,0) [0|0] "" Vector__XXX
 SG_ AMS_FLT_UV_Stack_04_C11 : 11|1@0+ (1,0) [0|0] "" Vector__XXX
 SG_ AMS_FLT_UV_Stack_04_C10 : 10|1@0+ (1,0) [0|0] "" Vector__XXX
 SG_ AMS_FLT_UV_Stack_04_C09 : 9|1@0+ (1,0) [0|0] "" Vector__XXX
 SG_ AMS_FLT_UV_Stack_04_C08 : 8|1@0+ (1,0) [0|0] "" Vector__XXX
 SG_ AMS_FLT_UV_Stack_04_C07 : 7|1@0+ (1,0) [0|0] "" Vector__XXX
 SG_ AMS_FLT_UV_Stack_04_C06 : 6|1@0+ (1,0) [0|0] "" Vector__XXX
 SG_ AMS_FLT_UV_Stack_04_C05 : 5|1@0+ (1,0) [0|0] "" Vector__XXX
 SG_ AMS_FLT_UV_Stack_04_C04 : 4|1@0+ (1,0) [0|0] "" Vector__XXX
 SG_ AMS_FLT_UV_Stack_04_C03 : 3|1@0+ (1,0) [0|0] "" Vector__XXX
 SG_ AMS_FLT_UV_Stack_04_C02 : 2|1@0+ (1,0) [0|0] "" Vector__XXX
 SG_ AMS_FLT_UV_Stack_04_C01 : 1|1@0+ (1,0) [0|0] "" Vector__XXX
 SG_ AMS_FLT_UV_Stack_04_C00 : 0|1@0+ (1,0) [0|0] "" Vector__XXX

BO_ 1124 Status_AMS_08_UV_Stack_0_3: 6 _04_HV_AMS
 SG_ AMS_FLT_UV_Stack_03_C11 : 47|1@0+ (1,0) [0|0] "" Vector__XXX
 SG_ AMS_FLT_UV_Stack_03_C10 : 46|1@0+ (1,0) [0|0] "" Vector__XXX
 SG_ AMS_FLT_UV_Stack_03_C09 : 45|1@0+ (1,0) [0|0] "" Vector__XXX
 SG_ AMS_FLT_UV_Stack_03_C08 : 44|1@0+ (1,0) [0|0] "" Vector__XXX
 SG_ AMS_FLT_UV_Stack_03_C07 : 43|1@0+ (1,0) [0|0] "" Vector__XXX
 SG_ AMS_FLT_UV_Stack_03_C06 : 42|1@0+ (1,0) [0|0] "" Vector__XXX
 SG_ AMS_FLT_UV_Stack_03_C05 : 41|1@0+ (1,0) [0|0] "" Vector__XXX
 SG_ AMS_FLT_UV_Stack_03_C04 : 40|1@0+ (1,0) [0|0] "" Vector__XXX
 SG_ AMS_FLT_UV_Stack_03_C03 : 39|1@0+ (1,0) [0|0] "" Vector__XXX
 SG_ AMS_FLT_UV_Stack_03_C02 : 38|1@0+ (1,0) [0|0] "" Vector__XXX
 SG_ AMS_FLT_UV_Stack_03_C01 : 37|1@0+ (1,0) [0|0] "" Vector__XXX
 SG_ AMS_FLT_UV_Stack_03_C00 : 36|1@0+ (1,0) [0|0] "" Vector__XXX
 SG_ AMS_FLT_UV_Stack_02_C11 : 35|1@0+ (1,0) [0|0] "" Vector__XXX
 SG_ AMS_FLT_UV_Stack_02_C10 : 34|1@0+ (1,0) [0|0] "" Vector__XXX
 SG_ AMS_FLT_UV_Stack_02_C09 : 33|1@0+ (1,0) [0|0] "" Vector__XXX
 SG_ AMS_FLT_UV_Stack_02_C08 : 32|1@0+ (1,0) [0|0] "" Vector__XXX
 SG_ AMS_FLT_UV_Stack_02_C07 : 31|1@0+ (1,0) [0|0] "" Vector__XXX
 SG_ AMS_FLT_UV_Stack_02_C06 : 30|1@0+ (1,0) [0|0] "" Vector__XXX
 SG_ AMS_FLT_UV_Stack_02_C05 : 29|1@0+ (1,0) [0|0] "" Vector__XXX
 SG_ AMS_FLT_UV_Stack_02_C04 : 28|1@0+ (1,0) [0|0] "" Vector__XXX
 SG_ AMS_FLT_UV_Stack_02_C03 : 27|1@0+ (1,0) [0|0] "" Vector__XXX
 SG_ AMS_FLT_UV_Stack_02_C02 : 26|1@0+ (1,0) [0|0] "" Vector__XXX
 SG_ AMS_FLT_UV_Stack_02_C01 : 25|1@0+ (1,0) [0|0] "" Vector__XXX
 SG_ AMS_FLT_UV_Stack_02_C00 : 24|1@0+ (1,0) [0|0] "" Vector__XXX
 SG_ AMS_FLT_UV_Stack_01_C11 : 23|1@0+ (1,0) [0|0] "" Vector__XXX
 SG_ AMS_FLT_UV_Stack_01_C10 : 22|1@0+ (1,0) [0|0] "" Vector__XXX
 SG_ AMS_FLT_UV_Stack_01_C09 : 21|1@0+ (1,0) [0|0] "" Vector__XXX
 SG_ AMS_FLT_UV_Stack_01_C08 : 20|1@0+ (1,0) [0|0] "" Vector__XXX
 SG_ AMS_FLT_UV_Stack_01_C07 : 19|1@0+ (1,0) [0|0] "" Vector__XXX
 SG_ AMS_FLT_UV_Stack_01_C06 : 18|1@0+ (1,0) [0|0] "" Vector__XXX
 SG_ AMS_FLT_UV_Stack_01_C05 : 17|1@0+ (1,0) [0|0] "" Vector__XXX
 SG_ AMS_FLT_UV_Stack_01_C04 : 16|1@0+ (1,0) [0|0] "" Vector__XXX
 SG_ AMS_FLT_UV_Stack_01_C03 : 15|1@0+ (1,0) [0|0] "" Vector__XXX
 SG_ AMS_FLT_UV_Stack_01_C02 : 14|1@0+ (1,0) [0|0] "" Vector__XXX
 SG_ AMS_FLT_UV_Stack_01_C01 : 13|1@0+ (1,0) [0|0] "" Vector__XXX
 SG_ AMS_FLT_UV_Stack_01_C00 : 12|1@0+ (1,0) [0|0] "" Vector__XXX
 SG_ AMS_FLT_UV_Stack_00_C11 : 11|1@0+ (1,0) [0|0] "" Vector__XXX
 SG_ AMS_FLT_UV_Stack_00_C10 : 10|1@0+ (1,0) [0|0] "" Vector__XXX
 SG_ AMS_FLT_UV_Stack_00_C09 : 9|1@0+ (1,0) [0|0] "" Vector__XXX
 SG_ AMS_FLT_UV_Stack_00_C08 : 8|1@0+ (1,0) [0|0] "" Vector__XXX
 SG_ AMS_FLT_UV_Stack_00_C07 : 7|1@0+ (1,0) [0|0] "" Vector__XXX
 SG_ AMS_FLT_UV_Stack_00_C06 : 6|1@0+ (1,0) [0|0] "" Vector__XXX
 SG_ AMS_FLT_UV_Stack_00_C05 : 5|1@0+ (1,0) [0|0] "" Vector__XXX
 SG_ AMS_FLT_UV_Stack_00_C04 : 4|1@0+ (1,0) [0|0] "" Vector__XXX
 SG_ AMS_FLT_UV_Stack_00_C03 : 3|1@0+ (1,0) [0|0] "" Vector__XXX
 SG_ AMS_FLT_UV_Stack_00_C02 : 2|1@0+ (1,0) [0|0] "" Vector__XXX
 SG_ AMS_FLT_UV_Stack_00_C01 : 1|1@0+ (1,0) [0|0] "" Vector__XXX
 SG_ AMS_FLT_UV_Stack_00_C00 : 0|1@0+ (1,0) [0|0] "" Vector__XXX

BO_ 1108 Status_AMS_07_OV_Stack_8_11: 6 _04_HV_AMS
 SG_ AMS_FLT_OV_Stack_11_C11 : 47|1@0+ (1,0) [0|0] "" Vector__XXX
 SG_ AMS_FLT_OV_Stack_11_C10 : 46|1@0+ (1,0) [0|0] "" Vector__XXX
 SG_ AMS_FLT_OV_Stack_11_C09 : 45|1@0+ (1,0) [0|0] "" Vector__XXX
 SG_ AMS_FLT_OV_Stack_11_C08 : 44|1@0+ (1,0) [0|0] "" Vector__XXX
 SG_ AMS_FLT_OV_Stack_11_C07 : 43|1@0+ (1,0) [0|0] "" Vector__XXX
 SG_ AMS_FLT_OV_Stack_11_C06 : 42|1@0+ (1,0) [0|0] "" Vector__XXX
 SG_ AMS_FLT_OV_Stack_11_C05 : 41|1@0+ (1,0) [0|0] "" Vector__XXX
 SG_ AMS_FLT_OV_Stack_11_C04 : 40|1@0+ (1,0) [0|0] "" Vector__XXX
 SG_ AMS_FLT_OV_Stack_11_C03 : 39|1@0+ (1,0) [0|0] "" Vector__XXX
 SG_ AMS_FLT_OV_Stack_11_C02 : 38|1@0+ (1,0) [0|0] "" Vector__XXX
 SG_ AMS_FLT_OV_Stack_11_C01 : 37|1@0+ (1,0) [0|0] "" Vector__XXX
 SG_ AMS_FLT_OV_Stack_11_C00 : 36|1@0+ (1,0) [0|0] "" Vector__XXX
 SG_ AMS_FLT_OV_Stack_10_C11 : 35|1@0+ (1,0) [0|0] "" Vector__XXX
 SG_ AMS_FLT_OV_Stack_10_C10 : 34|1@0+ (1,0) [0|0] "" Vector__XXX
 SG_ AMS_FLT_OV_Stack_10_C09 : 33|1@0+ (1,0) [0|0] "" Vector__XXX
 SG_ AMS_FLT_OV_Stack_10_C08 : 32|1@0+ (1,0) [0|0] "" Vector__XXX
 SG_ AMS_FLT_OV_Stack_10_C07 : 31|1@0+ (1,0) [0|0] "" Vector__XXX
 SG_ AMS_FLT_OV_Stack_10_C06 : 30|1@0+ (1,0) [0|0] "" Vector__XXX
 SG_ AMS_FLT_OV_Stack_10_C05 : 29|1@0+ (1,0) [0|0] "" Vector__XXX
 SG_ AMS_FLT_OV_Stack_10_C04 : 28|1@0+ (1,0) [0|0] "" Vector__XXX
 SG_ AMS_FLT_OV_Stack_10_C03 : 27|1@0+ (1,0) [0|0] "" Vector__XXX
 SG_ AMS_FLT_OV_Stack_10_C02 : 26|1@0+ (1,0) [0|0] "" Vector__XXX
 SG_ AMS_FLT_OV_Stack_10_C01 : 25|1@0+ (1,0) [0|0] "" Vector__XXX
 SG_ AMS_FLT_OV_Stack_10_C00 : 24|1@0+ (1,0) [0|0] "" Vector__XXX
 SG_ AMS_FLT_OV_Stack_09_C11 : 23|1@0+ (1,0) [0|0] "" Vector__XXX
 SG_ AMS_FLT_OV_Stack_09_C10 : 22|1@0+ (1,0) [0|0] "" Vector__XXX
 SG_ AMS_FLT_OV_Stack_09_C09 : 21|1@0+ (1,0) [0|0] "" Vector__XXX
 SG_ AMS_FLT_OV_Stack_09_C08 : 20|1@0+ (1,0) [0|0] "" Vector__XXX
 SG_ AMS_FLT_OV_Stack_09_C07 : 19|1@0+ (1,0) [0|0] "" Vector__XXX
 SG_ AMS_FLT_OV_Stack_09_C06 : 18|1@0+ (1,0) [0|0] "" Vector__XXX
 SG_ AMS_FLT_OV_Stack_09_C05 : 17|1@0+ (1,0) [0|0] "" Vector__XXX
 SG_ AMS_FLT_OV_Stack_09_C04 : 16|1@0+ (1,0) [0|0] "" Vector__XXX
 SG_ AMS_FLT_OV_Stack_09_C03 : 15|1@0+ (1,0) [0|0] "" Vector__XXX
 SG_ AMS_FLT_OV_Stack_09_C02 : 14|1@0+ (1,0) [0|0] "" Vector__XXX
 SG_ AMS_FLT_OV_Stack_09_C01 : 13|1@0+ (1,0) [0|0] "" Vector__XXX
 SG_ AMS_FLT_OV_Stack_09_C00 : 12|1@0+ (1,0) [0|0] "" Vector__XXX
 SG_ AMS_FLT_OV_Stack_08_C11 : 11|1@0+ (1,0) [0|0] "" Vector__XXX
 SG_ AMS_FLT_OV_Stack_08_C10 : 10|1@0+ (1,0) [0|0] "" Vector__XXX
 SG_ AMS_FLT_OV_Stack_08_C09 : 9|1@0+ (1,0) [0|0] "" Vector__XXX
 SG_ AMS_FLT_OV_Stack_08_C08 : 8|1@0+ (1,0) [0|0] "" Vector__XXX
 SG_ AMS_FLT_OV_Stack_08_C07 : 7|1@0+ (1,0) [0|0] "" Vector__XXX
 SG_ AMS_FLT_OV_Stack_08_C06 : 6|1@0+ (1,0) [0|0] "" Vector__XXX
 SG_ AMS_FLT_OV_Stack_08_C05 : 5|1@0+ (1,0) [0|0] "" Vector__XXX
 SG_ AMS_FLT_OV_Stack_08_C04 : 4|1@0+ (1,0) [0|0] "" Vector__XXX
 SG_ AMS_FLT_OV_Stack_08_C03 : 3|1@0+ (1,0) [0|0] "" Vector__XXX
 SG_ AMS_FLT_OV_Stack_08_C02 : 2|1@0+ (1,0) [0|0] "" Vector__XXX
 SG_ AMS_FLT_OV_Stack_08_C01 : 1|1@0+ (1,0) [0|0] "" Vector__XXX
 SG_ AMS_FLT_OV_Stack_08_C00 : 0|1@0+ (1,0) [0|0] "" Vector__XXX

BO_ 1092 Status_AMS_06_OV_Stack_4_7: 6 _04_HV_AMS
 SG_ AMS_FLT_OV_Stack_07_C11 : 47|1@0+ (1,0) [0|0] "" Vector__XXX
 SG_ AMS_FLT_OV_Stack_07_C10 : 46|1@0+ (1,0) [0|0] "" Vector__XXX
 SG_ AMS_FLT_OV_Stack_07_C09 : 45|1@0+ (1,0) [0|0] "" Vector__XXX
 SG_ AMS_FLT_OV_Stack_07_C08 : 44|1@0+ (1,0) [0|0] "" Vector__XXX
 SG_ AMS_FLT_OV_Stack_07_C07 : 43|1@0+ (1,0) [0|0] "" Vector__XXX
 SG_ AMS_FLT_OV_Stack_07_C06 : 42|1@0+ (1,0) [0|0] "" Vector__XXX
 SG_ AMS_FLT_OV_Stack_07_C05 : 41|1@0+ (1,0) [0|0] "" Vector__XXX
 SG_ AMS_FLT_OV_Stack_07_C04 : 40|1@0+ (1,0) [0|0] "" Vector__XXX
 SG_ AMS_FLT_OV_Stack_07_C03 : 39|1@0+ (1,0) [0|0] "" Vector__XXX
 SG_ AMS_FLT_OV_Stack_07_C02 : 38|1@0+ (1,0) [0|0] "" Vector__XXX
 SG_ AMS_FLT_OV_Stack_07_C01 : 37|1@0+ (1,0) [0|0] "" Vector__XXX
 SG_ AMS_FLT_OV_Stack_07_C00 : 36|1@0+ (1,0) [0|0] "" Vector__XXX
 SG_ AMS_FLT_OV_Stack_06_C11 : 35|1@0+ (1,0) [0|0] "" Vector__XXX
 SG_ AMS_FLT_OV_Stack_06_C10 : 34|1@0+ (1,0) [0|0] "" Vector__XXX
 SG_ AMS_FLT_OV_Stack_06_C09 : 33|1@0+ (1,0) [0|0] "" Vector__XXX
 SG_ AMS_FLT_OV_Stack_06_C08 : 32|1@0+ (1,0) [0|0] "" Vector__XXX
 SG_ AMS_FLT_OV_Stack_06_C07 : 31|1@0+ (1,0) [0|0] "" Vector__XXX
 SG_ AMS_FLT_OV_Stack_06_C06 : 30|1@0+ (1,0) [0|0] "" Vector__XXX
 SG_ AMS_FLT_OV_Stack_06_C05 : 29|1@0+ (1,0) [0|0] "" Vector__XXX
 SG_ AMS_FLT_OV_Stack_06_C04 : 28|1@0+ (1,0) [0|0] "" Vector__XXX
 SG_ AMS_FLT_OV_Stack_06_C03 : 27|1@0+ (1,0) [0|0] "" Vector__XXX
 SG_ AMS_FLT_OV_Stack_06_C02 : 26|1@0+ (1,0) [0|0] "" Vector__XXX
 SG_ AMS_FLT_OV_Stack_06_C01 : 25|1@0+ (1,0) [0|0] "" Vector__XXX
 SG_ AMS_FLT_OV_Stack_06_C00 : 24|1@0+ (1,0) [0|0] "" Vector__XXX
 SG_ AMS_FLT_OV_Stack_05_C11 : 23|1@0+ (1,0) [0|0] "" Vector__XXX
 SG_ AMS_FLT_OV_Stack_05_C10 : 22|1@0+ (1,0) [0|0] "" Vector__XXX
 SG_ AMS_FLT_OV_Stack_05_C09 : 21|1@0+ (1,0) [0|0] "" Vector__XXX
 SG_ AMS_FLT_OV_Stack_05_C08 : 20|1@0+ (1,0) [0|0] "" Vector__XXX
 SG_ AMS_FLT_OV_Stack_05_C07 : 19|1@0+ (1,0) [0|0] "" Vector__XXX
 SG_ AMS_FLT_OV_Stack_05_C06 : 18|1@0+ (1,0) [0|0] "" Vector__XXX
 SG_ AMS_FLT_OV_Stack_05_C05 : 17|1@0+ (1,0) [0|0] "" Vector__XXX
 SG_ AMS_FLT_OV_Stack_05_C04 : 16|1@0+ (1,0) [0|0] "" Vector__XXX
 SG_ AMS_FLT_OV_Stack_05_C03 : 15|1@0+ (1,0) [0|0] "" Vector__XXX
 SG_ AMS_FLT_OV_Stack_05_C02 : 14|1@0+ (1,0) [0|0] "" Vector__XXX
 SG_ AMS_FLT_OV_Stack_05_C01 : 13|1@0+ (1,0) [0|0] "" Vector__XXX
 SG_ AMS_FLT_OV_Stack_05_C00 : 12|1@0+ (1,0) [0|0] "" Vector__XXX
 SG_ AMS_FLT_OV_Stack_04_C11 : 11|1@0+ (1,0) [0|0] "" Vector__XXX
 SG_ AMS_FLT_OV_Stack_04_C10 : 10|1@0+ (1,0) [0|0] "" Vector__XXX
 SG_ AMS_FLT_OV_Stack_04_C09 : 9|1@0+ (1,0) [0|0] "" Vector__XXX
 SG_ AMS_FLT_OV_Stack_04_C08 : 8|1@0+ (1,0) [0|0] "" Vector__XXX
 SG_ AMS_FLT_OV_Stack_04_C07 : 7|1@0+ (1,0) [0|0] "" Vector__XXX
 SG_ AMS_FLT_OV_Stack_04_C06 : 6|1@0+ (1,0) [0|0] "" Vector__XXX
 SG_ AMS_FLT_OV_Stack_04_C05 : 5|1@0+ (1,0) [0|0] "" Vector__XXX
 SG_ AMS_FLT_OV_Stack_04_C04 : 4|1@0+ (1,0) [0|0] "" Vector__XXX
 SG_ AMS_FLT_OV_Stack_04_C03 : 3|1@0+ (1,0) [0|0] "" Vector__XXX
 SG_ AMS_FLT_OV_Stack_04_C02 : 2|1@0+ (1,0) [0|0] "" Vector__XXX
 SG_ AMS_FLT_OV_Stack_04_C01 : 1|1@0+ (1,0) [0|0] "" Vector__XXX
 SG_ AMS_FLT_OV_Stack_04_C00 : 0|1@0+ (1,0) [0|0] "" Vector__XXX

BO_ 1076 Status_AMS_05_OV_Stack_0_3: 6 _04_HV_AMS
 SG_ AMS_FLT_OV_Stack_03_C11 : 47|1@0+ (1,0) [0|0] "" Vector__XXX
 SG_ AMS_FLT_OV_Stack_03_C10 : 46|1@0+ (1,0) [0|0] "" Vector__XXX
 SG_ AMS_FLT_OV_Stack_03_C09 : 45|1@0+ (1,0) [0|0] "" Vector__XXX
 SG_ AMS_FLT_OV_Stack_03_C08 : 44|1@0+ (1,0) [0|0] "" Vector__XXX
 SG_ AMS_FLT_OV_Stack_03_C07 : 43|1@0+ (1,0) [0|0] "" Vector__XXX
 SG_ AMS_FLT_OV_Stack_03_C06 : 42|1@0+ (1,0) [0|0] "" Vector__XXX
 SG_ AMS_FLT_OV_Stack_03_C05 : 41|1@0+ (1,0) [0|0] "" Vector__XXX
 SG_ AMS_FLT_OV_Stack_03_C04 : 40|1@0+ (1,0) [0|0] "" Vector__XXX
 SG_ AMS_FLT_OV_Stack_03_C03 : 39|1@0+ (1,0) [0|0] "" Vector__XXX
 SG_ AMS_FLT_OV_Stack_03_C02 : 38|1@0+ (1,0) [0|0] "" Vector__XXX
 SG_ AMS_FLT_OV_Stack_03_C01 : 37|1@0+ (1,0) [0|0] "" Vector__XXX
 SG_ AMS_FLT_OV_Stack_03_C00 : 36|1@0+ (1,0) [0|0] "" Vector__XXX
 SG_ AMS_FLT_OV_Stack_02_C11 : 35|1@0+ (1,0) [0|0] "" Vector__XXX
 SG_ AMS_FLT_OV_Stack_02_C10 : 34|1@0+ (1,0) [0|0] "" Vector__XXX
 SG_ AMS_FLT_OV_Stack_02_C09 : 33|1@0+ (1,0) [0|0] "" Vector__XXX
 SG_ AMS_FLT_OV_Stack_02_C08 : 32|1@0+ (1,0) [0|0] "" Vector__XXX
 SG_ AMS_FLT_OV_Stack_02_C07 : 31|1@0+ (1,0) [0|0] "" Vector__XXX
 SG_ AMS_FLT_OV_Stack_02_C06 : 30|1@0+ (1,0) [0|0] "" Vector__XXX
 SG_ AMS_FLT_OV_Stack_02_C05 : 29|1@0+ (1,0) [0|0] "" Vector__XXX
 SG_ AMS_FLT_OV_Stack_02_C04 : 28|1@0+ (1,0) [0|0] "" Vector__XXX
 SG_ AMS_FLT_OV_Stack_02_C03 : 27|1@0+ (1,0) [0|0] "" Vector__XXX
 SG_ AMS_FLT_OV_Stack_02_C02 : 26|1@0+ (1,0) [0|0] "" Vector__XXX
 SG_ AMS_FLT_OV_Stack_02_C01 : 25|1@0+ (1,0) [0|0] "" Vector__XXX
 SG_ AMS_FLT_OV_Stack_02_C00 : 24|1@0+ (1,0) [0|0] "" Vector__XXX
 SG_ AMS_FLT_OV_Stack_01_C11 : 23|1@0+ (1,0) [0|0] "" Vector__XXX
 SG_ AMS_FLT_OV_Stack_01_C10 : 22|1@0+ (1,0) [0|0] "" Vector__XXX
 SG_ AMS_FLT_OV_Stack_01_C09 : 21|1@0+ (1,0) [0|0] "" Vector__XXX
 SG_ AMS_FLT_OV_Stack_01_C08 : 20|1@0+ (1,0) [0|0] "" Vector__XXX
 SG_ AMS_FLT_OV_Stack_01_C07 : 19|1@0+ (1,0) [0|0] "" Vector__XXX
 SG_ AMS_FLT_OV_Stack_01_C06 : 18|1@0+ (1,0) [0|0] "" Vector__XXX
 SG_ AMS_FLT_OV_Stack_01_C05 : 17|1@0+ (1,0) [0|0] "" Vector__XXX
 SG_ AMS_FLT_OV_Stack_01_C04 : 16|1@0+ (1,0) [0|0] "" Vector__XXX
 SG_ AMS_FLT_OV_Stack_01_C03 : 15|1@0+ (1,0) [0|0] "" Vector__XXX
 SG_ AMS_FLT_OV_Stack_01_C02 : 14|1@0+ (1,0) [0|0] "" Vector__XXX
 SG_ AMS_FLT_OV_Stack_01_C01 : 13|1@0+ (1,0) [0|0] "" Vector__XXX
 SG_ AMS_FLT_OV_Stack_01_C00 : 12|1@0+ (1,0) [0|0] "" Vector__XXX
 SG_ AMS_FLT_OV_Stack_00_C11 : 11|1@0+ (1,0) [0|0] "" Vector__XXX
 SG_ AMS_FLT_OV_Stack_00_C10 : 10|1@0+ (1,0) [0|0] "" Vector__XXX
 SG_ AMS_FLT_OV_Stack_00_C09 : 9|1@0+ (1,0) [0|0] "" Vector__XXX
 SG_ AMS_FLT_OV_Stack_00_C08 : 8|1@0+ (1,0) [0|0] "" Vector__XXX
 SG_ AMS_FLT_OV_Stack_00_C07 : 7|1@0+ (1,0) [0|0] "" Vector__XXX
 SG_ AMS_FLT_OV_Stack_00_C06 : 6|1@0+ (1,0) [0|0] "" Vector__XXX
 SG_ AMS_FLT_OV_Stack_00_C05 : 5|1@0+ (1,0) [0|0] "" Vector__XXX
 SG_ AMS_FLT_OV_Stack_00_C04 : 4|1@0+ (1,0) [0|0] "" Vector__XXX
 SG_ AMS_FLT_OV_Stack_00_C03 : 3|1@0+ (1,0) [0|0] "" Vector__XXX
 SG_ AMS_FLT_OV_Stack_00_C02 : 2|1@0+ (1,0) [0|0] "" Vector__XXX
 SG_ AMS_FLT_OV_Stack_00_C01 : 1|1@0+ (1,0) [0|0] "" Vector__XXX
 SG_ AMS_FLT_OV_Stack_00_C00 : 0|1@0+ (1,0) [0|0] "" Vector__XXX

BO_ 1060 Status_AMS_04_FStat_Stack_8_11: 6 _04_HV_AMS
 SG_ AMS_FLT_WDGD_Stack_11 : 37|1@0+ (1,0) [0|0] "" Vector__XXX
 SG_ AMS_FLT_Under_Voltage_Stack_11 : 40|1@0+ (1,0) [0|0] "" Vector__XXX
 SG_ AMS_FLT_Regulator_Stack_11 : 46|1@0+ (1,0) [0|0] "" Vector__XXX
 SG_ AMS_FLT_Reference_Stack_11 : 45|1@0+ (1,0) [0|0] "" Vector__XXX
 SG_ AMS_FLT_Parity_Stack_11 : 44|1@0+ (1,0) [0|0] "" Vector__XXX
 SG_ AMS_FLT_Over_Voltage_Stack_11 : 39|1@0+ (1,0) [0|0] "" Vector__XXX
 SG_ AMS_FLT_Over_Temp_Stack_11 : 38|1@0+ (1,0) [0|0] "" Vector__XXX
 SG_ AMS_FLT_Oscillator_Stack_11 : 36|1@0+ (1,0) [0|0] "" Vector__XXX
 SG_ AMS_FLT_Open_Wire_VSS_Stack_11 : 43|1@0+ (1,0) [0|0] "" Vector__XXX
 SG_ AMS_FLT_Open_Wire_Vbat_Stack_11 : 42|1@0+ (1,0) [0|0] "" Vector__XXX
 SG_ AMS_FLT_Open_Wire_Stack_11 : 41|1@0+ (1,0) [0|0] "" Vector__XXX
 SG_ AMS_FLT_MUX_Stack_11 : 47|1@0+ (1,0) [0|0] "" Vector__XXX
 SG_ AMS_FLT_WDGD_Stack_10 : 25|1@0+ (1,0) [0|0] "" Vector__XXX
 SG_ AMS_FLT_Under_Voltage_Stack_10 : 28|1@0+ (1,0) [0|0] "" Vector__XXX
 SG_ AMS_FLT_Regulator_Stack_10 : 34|1@0+ (1,0) [0|0] "" Vector__XXX
 SG_ AMS_FLT_Reference_Stack_10 : 33|1@0+ (1,0) [0|0] "" Vector__XXX
 SG_ AMS_FLT_Parity_Stack_10 : 32|1@0+ (1,0) [0|0] "" Vector__XXX
 SG_ AMS_FLT_Over_Voltage_Stack_10 : 27|1@0+ (1,0) [0|0] "" Vector__XXX
 SG_ AMS_FLT_Over_Temp_Stack_10 : 26|1@0+ (1,0) [0|0] "" Vector__XXX
 SG_ AMS_FLT_Oscillator_Stack_10 : 24|1@0+ (1,0) [0|0] "" Vector__XXX
 SG_ AMS_FLT_Open_Wire_VSS_Stack_10 : 31|1@0+ (1,0) [0|0] "" Vector__XXX
 SG_ AMS_FLT_Open_Wire_Vbat_Stack_10 : 30|1@0+ (1,0) [0|0] "" Vector__XXX
 SG_ AMS_FLT_Open_Wire_Stack_10 : 29|1@0+ (1,0) [0|0] "" Vector__XXX
 SG_ AMS_FLT_MUX_Stack_10 : 35|1@0+ (1,0) [0|0] "" Vector__XXX
 SG_ AMS_FLT_Open_Wire_VSS_Stack_09 : 19|1@0+ (1,0) [0|0] "" Vector__XXX
 SG_ AMS_FLT_WDGD_Stack_09 : 13|1@0+ (1,0) [0|0] "" Vector__XXX
 SG_ AMS_FLT_Under_Voltage_Stack_09 : 16|1@0+ (1,0) [0|0] "" Vector__XXX
 SG_ AMS_FLT_Regulator_Stack_09 : 22|1@0+ (1,0) [0|0] "" Vector__XXX
 SG_ AMS_FLT_Reference_Stack_09 : 21|1@0+ (1,0) [0|0] "" Vector__XXX
 SG_ AMS_FLT_Parity_Stack_09 : 20|1@0+ (1,0) [0|0] "" Vector__XXX
 SG_ AMS_FLT_Over_Voltage_Stack_09 : 15|1@0+ (1,0) [0|0] "" Vector__XXX
 SG_ AMS_FLT_Over_Temp_Stack_09 : 14|1@0+ (1,0) [0|0] "" Vector__XXX
 SG_ AMS_FLT_Oscillator_Stack_09 : 12|1@0+ (1,0) [0|0] "" Vector__XXX
 SG_ AMS_FLT_Open_Wire_Vbat_Stack_09 : 18|1@0+ (1,0) [0|0] "" Vector__XXX
 SG_ AMS_FLT_Open_Wire_Stack_09 : 17|1@0+ (1,0) [0|0] "" Vector__XXX
 SG_ AMS_FLT_MUX_Stack_09 : 23|1@0+ (1,0) [0|0] "" Vector__XXX
 SG_ AMS_FLT_WDGD_Stack_08 : 1|1@0+ (1,0) [0|0] "" Vector__XXX
 SG_ AMS_FLT_Under_Voltage_Stack_08 : 4|1@0+ (1,0) [0|0] "" Vector__XXX
 SG_ AMS_FLT_Regulator_Stack_08 : 10|1@0+ (1,0) [0|0] "" Vector__XXX
 SG_ AMS_FLT_Reference_Stack_08 : 9|1@0+ (1,0) [0|0] "" Vector__XXX
 SG_ AMS_FLT_Parity_Stack_08 : 8|1@0+ (1,0) [0|0] "" Vector__XXX
 SG_ AMS_FLT_Over_Voltage_Stack_08 : 3|1@0+ (1,0) [0|0] "" Vector__XXX
 SG_ AMS_FLT_Over_Temp_Stack_08 : 2|1@0+ (1,0) [0|0] "" Vector__XXX
 SG_ AMS_FLT_Oscillator_Stack_08 : 0|1@0+ (1,0) [0|0] "" Vector__XXX
 SG_ AMS_FLT_Open_Wire_VSS_Stack_08 : 6|1@0+ (1,0) [0|0] "" Vector__XXX
 SG_ AMS_FLT_Open_Wire_Vbat_Stack_08 : 7|1@0+ (1,0) [0|0] "" Vector__XXX
 SG_ AMS_FLT_Open_Wire_Stack_08 : 5|1@0+ (1,0) [0|0] "" Vector__XXX
 SG_ AMS_FLT_MUX_Stack_08 : 11|1@0+ (1,0) [0|0] "" Vector__XXX

BO_ 1044 Status_AMS_03_FStat_Stack_4_7: 6 _04_HV_AMS
 SG_ AMS_FLT_WDGD_Stack_07 : 37|1@0+ (1,0) [0|0] "" Vector__XXX
 SG_ AMS_FLT_Under_Voltage_Stack_07 : 40|1@0+ (1,0) [0|0] "" Vector__XXX
 SG_ AMS_FLT_Regulator_Stack_07 : 46|1@0+ (1,0) [0|0] "" Vector__XXX
 SG_ AMS_FLT_Reference_Stack_07 : 45|1@0+ (1,0) [0|0] "" Vector__XXX
 SG_ AMS_FLT_Parity_Stack_07 : 44|1@0+ (1,0) [0|0] "" Vector__XXX
 SG_ AMS_FLT_Over_Voltage_Stack_07 : 39|1@0+ (1,0) [0|0] "" Vector__XXX
 SG_ AMS_FLT_Over_Temp_Stack_07 : 38|1@0+ (1,0) [0|0] "" Vector__XXX
 SG_ AMS_FLT_Oscillator_Stack_07 : 36|1@0+ (1,0) [0|0] "" Vector__XXX
 SG_ AMS_FLT_Open_Wire_VSS_Stack_07 : 43|1@0+ (1,0) [0|0] "" Vector__XXX
 SG_ AMS_FLT_Open_Wire_Vbat_Stack_07 : 42|1@0+ (1,0) [0|0] "" Vector__XXX
 SG_ AMS_FLT_Open_Wire_Stack_07 : 41|1@0+ (1,0) [0|0] "" Vector__XXX
 SG_ AMS_FLT_MUX_Stack_07 : 47|1@0+ (1,0) [0|0] "" Vector__XXX
 SG_ AMS_FLT_WDGD_Stack_06 : 25|1@0+ (1,0) [0|0] "" Vector__XXX
 SG_ AMS_FLT_Under_Voltage_Stack_06 : 28|1@0+ (1,0) [0|0] "" Vector__XXX
 SG_ AMS_FLT_Regulator_Stack_06 : 34|1@0+ (1,0) [0|0] "" Vector__XXX
 SG_ AMS_FLT_Reference_Stack_06 : 33|1@0+ (1,0) [0|0] "" Vector__XXX
 SG_ AMS_FLT_Parity_Stack_06 : 32|1@0+ (1,0) [0|0] "" Vector__XXX
 SG_ AMS_FLT_Over_Voltage_Stack_06 : 27|1@0+ (1,0) [0|0] "" Vector__XXX
 SG_ AMS_FLT_Over_Temp_Stack_06 : 26|1@0+ (1,0) [0|0] "" Vector__XXX
 SG_ AMS_FLT_Oscillator_Stack_06 : 24|1@0+ (1,0) [0|0] "" Vector__XXX
 SG_ AMS_FLT_Open_Wire_VSS_Stack_06 : 31|1@0+ (1,0) [0|0] "" Vector__XXX
 SG_ AMS_FLT_Open_Wire_Vbat_Stack_06 : 30|1@0+ (1,0) [0|0] "" Vector__XXX
 SG_ AMS_FLT_Open_Wire_Stack_06 : 29|1@0+ (1,0) [0|0] "" Vector__XXX
 SG_ AMS_FLT_MUX_Stack_06 : 35|1@0+ (1,0) [0|0] "" Vector__XXX
 SG_ AMS_FLT_Open_Wire_VSS_Stack_05 : 19|1@0+ (1,0) [0|0] "" Vector__XXX
 SG_ AMS_FLT_WDGD_Stack_05 : 13|1@0+ (1,0) [0|0] "" Vector__XXX
 SG_ AMS_FLT_Under_Voltage_Stack_05 : 16|1@0+ (1,0) [0|0] "" Vector__XXX
 SG_ AMS_FLT_Regulator_Stack_05 : 22|1@0+ (1,0) [0|0] "" Vector__XXX
 SG_ AMS_FLT_Reference_Stack_05 : 21|1@0+ (1,0) [0|0] "" Vector__XXX
 SG_ AMS_FLT_Parity_Stack_05 : 20|1@0+ (1,0) [0|0] "" Vector__XXX
 SG_ AMS_FLT_Over_Voltage_Stack_05 : 15|1@0+ (1,0) [0|0] "" Vector__XXX
 SG_ AMS_FLT_Over_Temp_Stack_05 : 14|1@0+ (1,0) [0|0] "" Vector__XXX
 SG_ AMS_FLT_Oscillator_Stack_05 : 12|1@0+ (1,0) [0|0] "" Vector__XXX
 SG_ AMS_FLT_Open_Wire_Vbat_Stack_05 : 18|1@0+ (1,0) [0|0] "" Vector__XXX
 SG_ AMS_FLT_Open_Wire_Stack_05 : 17|1@0+ (1,0) [0|0] "" Vector__XXX
 SG_ AMS_FLT_MUX_Stack_05 : 23|1@0+ (1,0) [0|0] "" Vector__XXX
 SG_ AMS_FLT_WDGD_Stack_04 : 1|1@0+ (1,0) [0|0] "" Vector__XXX
 SG_ AMS_FLT_Under_Voltage_Stack_04 : 4|1@0+ (1,0) [0|0] "" Vector__XXX
 SG_ AMS_FLT_Regulator_Stack_04 : 10|1@0+ (1,0) [0|0] "" Vector__XXX
 SG_ AMS_FLT_Reference_Stack_04 : 9|1@0+ (1,0) [0|0] "" Vector__XXX
 SG_ AMS_FLT_Parity_Stack_04 : 8|1@0+ (1,0) [0|0] "" Vector__XXX
 SG_ AMS_FLT_Over_Voltage_Stack_04 : 3|1@0+ (1,0) [0|0] "" Vector__XXX
 SG_ AMS_FLT_Over_Temp_Stack_04 : 2|1@0+ (1,0) [0|0] "" Vector__XXX
 SG_ AMS_FLT_Oscillator_Stack_04 : 0|1@0+ (1,0) [0|0] "" Vector__XXX
 SG_ AMS_FLT_Open_Wire_VSS_Stack_04 : 6|1@0+ (1,0) [0|0] "" Vector__XXX
 SG_ AMS_FLT_Open_Wire_Vbat_Stack_04 : 7|1@0+ (1,0) [0|0] "" Vector__XXX
 SG_ AMS_FLT_Open_Wire_Stack_04 : 5|1@0+ (1,0) [0|0] "" Vector__XXX
 SG_ AMS_FLT_MUX_Stack_04 : 11|1@0+ (1,0) [0|0] "" Vector__XXX

BO_ 1028 Status_AMS_02_FStat_Stack_0_3: 6 _04_HV_AMS
 SG_ AMS_FLT_Regulator_Stack_01 : 22|1@0+ (1,0) [0|0] "" Vector__XXX
 SG_ AMS_FLT_Open_Wire_Stack_01 : 17|1@0+ (1,0) [0|0] "" Vector__XXX
 SG_ AMS_FLT_WDGD_Stack_03 : 37|1@0+ (1,0) [0|0] "" Vector__XXX
 SG_ AMS_FLT_Under_Voltage_Stack_03 : 40|1@0+ (1,0) [0|0] "" Vector__XXX
 SG_ AMS_FLT_Regulator_Stack_03 : 46|1@0+ (1,0) [0|0] "" Vector__XXX
 SG_ AMS_FLT_Reference_Stack_03 : 45|1@0+ (1,0) [0|0] "" Vector__XXX
 SG_ AMS_FLT_Parity_Stack_03 : 44|1@0+ (1,0) [0|0] "" Vector__XXX
 SG_ AMS_FLT_Over_Voltage_Stack_03 : 39|1@0+ (1,0) [0|0] "" Vector__XXX
 SG_ AMS_FLT_Over_Temp_Stack_03 : 38|1@0+ (1,0) [0|0] "" Vector__XXX
 SG_ AMS_FLT_Oscillator_Stack_03 : 36|1@0+ (1,0) [0|0] "" Vector__XXX
 SG_ AMS_FLT_Open_Wire_VSS_Stack_03 : 43|1@0+ (1,0) [0|0] "" Vector__XXX
 SG_ AMS_FLT_Open_Wire_Vbat_Stack_03 : 42|1@0+ (1,0) [0|0] "" Vector__XXX
 SG_ AMS_FLT_Open_Wire_Stack_03 : 41|1@0+ (1,0) [0|0] "" Vector__XXX
 SG_ AMS_FLT_MUX_Stack_03 : 47|1@0+ (1,0) [0|0] "" Vector__XXX
 SG_ AMS_FLT_WDGD_Stack_02 : 25|1@0+ (1,0) [0|0] "" Vector__XXX
 SG_ AMS_FLT_Under_Voltage_Stack_02 : 28|1@0+ (1,0) [0|0] "" Vector__XXX
 SG_ AMS_FLT_Regulator_Stack_02 : 34|1@0+ (1,0) [0|0] "" Vector__XXX
 SG_ AMS_FLT_Reference_Stack_02 : 33|1@0+ (1,0) [0|0] "" Vector__XXX
 SG_ AMS_FLT_Parity_Stack_02 : 32|1@0+ (1,0) [0|0] "" Vector__XXX
 SG_ AMS_FLT_Over_Voltage_Stack_02 : 27|1@0+ (1,0) [0|0] "" Vector__XXX
 SG_ AMS_FLT_Over_Temp_Stack_02 : 26|1@0+ (1,0) [0|0] "" Vector__XXX
 SG_ AMS_FLT_Oscillator_Stack_02 : 24|1@0+ (1,0) [0|0] "" Vector__XXX
 SG_ AMS_FLT_Open_Wire_VSS_Stack_02 : 31|1@0+ (1,0) [0|0] "" Vector__XXX
 SG_ AMS_FLT_Open_Wire_Vbat_Stack_02 : 30|1@0+ (1,0) [0|0] "" Vector__XXX
 SG_ AMS_FLT_Open_Wire_Stack_02 : 29|1@0+ (1,0) [0|0] "" Vector__XXX
 SG_ AMS_FLT_MUX_Stack_02 : 35|1@0+ (1,0) [0|0] "" Vector__XXX
 SG_ AMS_FLT_Open_Wire_VSS_Stack_01 : 19|1@0+ (1,0) [0|0] "" Vector__XXX
 SG_ AMS_FLT_WDGD_Stack_01 : 13|1@0+ (1,0) [0|0] "" Vector__XXX
 SG_ AMS_FLT_Under_Voltage_Stack_01 : 16|1@0+ (1,0) [0|0] "" Vector__XXX
 SG_ AMS_FLT_Reference_Stack_01 : 21|1@0+ (1,0) [0|0] "" Vector__XXX
 SG_ AMS_FLT_Parity_Stack_01 : 20|1@0+ (1,0) [0|0] "" Vector__XXX
 SG_ AMS_FLT_Over_Voltage_Stack_01 : 15|1@0+ (1,0) [0|0] "" Vector__XXX
 SG_ AMS_FLT_Over_Temp_Stack_01 : 14|1@0+ (1,0) [0|0] "" Vector__XXX
 SG_ AMS_FLT_Oscillator_Stack_01 : 12|1@0+ (1,0) [0|0] "" Vector__XXX
 SG_ AMS_FLT_Open_Wire_Vbat_Stack_01 : 18|1@0+ (1,0) [0|0] "" Vector__XXX
 SG_ AMS_FLT_MUX_Stack_01 : 23|1@0+ (1,0) [0|0] "" Vector__XXX
 SG_ AMS_FLT_WDGD_Stack_00 : 1|1@0+ (1,0) [0|0] "" Vector__XXX
 SG_ AMS_FLT_Under_Voltage_Stack_00 : 4|1@0+ (1,0) [0|0] "" Vector__XXX
 SG_ AMS_FLT_Regulator_Stack_00 : 10|1@0+ (1,0) [0|0] "" Vector__XXX
 SG_ AMS_FLT_Reference_Stack_00 : 9|1@0+ (1,0) [0|0] "" Vector__XXX
 SG_ AMS_FLT_Parity_Stack_00 : 8|1@0+ (1,0) [0|0] "" Vector__XXX
 SG_ AMS_FLT_Over_Voltage_Stack_00 : 3|1@0+ (1,0) [0|0] "" Vector__XXX
 SG_ AMS_FLT_Over_Temp_Stack_00 : 2|1@0+ (1,0) [0|0] "" Vector__XXX
 SG_ AMS_FLT_Oscillator_Stack_00 : 0|1@0+ (1,0) [0|0] "" Vector__XXX
 SG_ AMS_FLT_Open_Wire_VSS_Stack_00 : 7|1@0+ (1,0) [0|0] "" Vector__XXX
 SG_ AMS_FLT_Open_Wire_Vbat_Stack_00 : 6|1@0+ (1,0) [0|0] "" Vector__XXX
 SG_ AMS_FLT_Open_Wire_Stack_00 : 5|1@0+ (1,0) [0|0] "" Vector__XXX
 SG_ AMS_FLT_MUX_Stack_00 : 11|1@0+ (1,0) [0|0] "" Vector__XXX

BO_ 868 AMS_Bal_Info_Stack_0_3: 8 _04_HV_AMS
 SG_ AMS_BalInfo_Stack_03_C11 : 59|1@0+ (1,0) [0|0] "" Vector__XXX
 SG_ AMS_BalInfo_Stack_03_C10 : 58|1@0+ (1,0) [0|0] "" Vector__XXX
 SG_ AMS_BalInfo_Stack_03_C09 : 57|1@0+ (1,0) [0|0] "" Vector__XXX
 SG_ AMS_BalInfo_Stack_03_C08 : 56|1@0+ (1,0) [0|0] "" Vector__XXX
 SG_ AMS_BalInfo_Stack_03_C07 : 55|1@0+ (1,0) [0|0] "" Vector__XXX
 SG_ AMS_BalInfo_Stack_03_C06 : 54|1@0+ (1,0) [0|0] "" Vector__XXX
 SG_ AMS_BalInfo_Stack_03_C05 : 53|1@0+ (1,0) [0|0] "" Vector__XXX
 SG_ AMS_BalInfo_Stack_03_C04 : 52|1@0+ (1,0) [0|0] "" Vector__XXX
 SG_ AMS_BalInfo_Stack_03_C03 : 51|1@0+ (1,0) [0|0] "" Vector__XXX
 SG_ AMS_BalInfo_Stack_03_C02 : 50|1@0+ (1,0) [0|0] "" Vector__XXX
 SG_ AMS_BalInfo_Stack_03_C01 : 49|1@0+ (1,0) [0|0] "" Vector__XXX
 SG_ AMS_BalInfo_Stack_03_C00 : 48|1@0+ (1,0) [0|0] "" Vector__XXX
 SG_ AMS_BalInfo_Stack_02_C11 : 43|1@0+ (1,0) [0|0] "" Vector__XXX
 SG_ AMS_BalInfo_Stack_02_C10 : 42|1@0+ (1,0) [0|0] "" Vector__XXX
 SG_ AMS_BalInfo_Stack_02_C09 : 41|1@0+ (1,0) [0|0] "" Vector__XXX
 SG_ AMS_BalInfo_Stack_02_C08 : 40|1@0+ (1,0) [0|0] "" Vector__XXX
 SG_ AMS_BalInfo_Stack_02_C07 : 39|1@0+ (1,0) [0|0] "" Vector__XXX
 SG_ AMS_BalInfo_Stack_02_C06 : 38|1@0+ (1,0) [0|0] "" Vector__XXX
 SG_ AMS_BalInfo_Stack_02_C05 : 37|1@0+ (1,0) [0|0] "" Vector__XXX
 SG_ AMS_BalInfo_Stack_02_C04 : 36|1@0+ (1,0) [0|0] "" Vector__XXX
 SG_ AMS_BalInfo_Stack_02_C03 : 35|1@0+ (1,0) [0|0] "" Vector__XXX
 SG_ AMS_BalInfo_Stack_02_C02 : 34|1@0+ (1,0) [0|0] "" Vector__XXX
 SG_ AMS_BalInfo_Stack_02_C01 : 33|1@0+ (1,0) [0|0] "" Vector__XXX
 SG_ AMS_BalInfo_Stack_02_C00 : 32|1@0+ (1,0) [0|0] "" Vector__XXX
 SG_ AMS_BalInfo_Stack_01_C11 : 27|1@0+ (1,0) [0|0] "" Vector__XXX
 SG_ AMS_BalInfo_Stack_01_C10 : 26|1@0+ (1,0) [0|0] "" Vector__XXX
 SG_ AMS_BalInfo_Stack_01_C09 : 25|1@0+ (1,0) [0|0] "" Vector__XXX
 SG_ AMS_BalInfo_Stack_01_C08 : 24|1@0+ (1,0) [0|0] "" Vector__XXX
 SG_ AMS_BalInfo_Stack_01_C07 : 23|1@0+ (1,0) [0|0] "" Vector__XXX
 SG_ AMS_BalInfo_Stack_01_C06 : 22|1@0+ (1,0) [0|0] "" Vector__XXX
 SG_ AMS_BalInfo_Stack_01_C05 : 21|1@0+ (1,0) [0|0] "" Vector__XXX
 SG_ AMS_BalInfo_Stack_01_C04 : 20|1@0+ (1,0) [0|0] "" Vector__XXX
 SG_ AMS_BalInfo_Stack_01_C03 : 19|1@0+ (1,0) [0|0] "" Vector__XXX
 SG_ AMS_BalInfo_Stack_01_C02 : 18|1@0+ (1,0) [0|0] "" Vector__XXX
 SG_ AMS_BalInfo_Stack_01_C01 : 17|1@0+ (1,0) [0|0] "" Vector__XXX
 SG_ AMS_BalInfo_Stack_01_C00 : 16|1@0+ (1,0) [0|0] "" Vector__XXX
 SG_ AMS_BalInfo_Stack_00_C11 : 11|1@0+ (1,0) [0|0] "" Vector__XXX
 SG_ AMS_BalInfo_Stack_00_C10 : 10|1@0+ (1,0) [0|0] "" Vector__XXX
 SG_ AMS_BalInfo_Stack_00_C09 : 9|1@0+ (1,0) [0|0] "" Vector__XXX
 SG_ AMS_BalInfo_Stack_00_C08 : 8|1@0+ (1,0) [0|0] "" Vector__XXX
 SG_ AMS_BalInfo_Stack_00_C07 : 7|1@0+ (1,0) [0|0] "" Vector__XXX
 SG_ AMS_BalInfo_Stack_00_C06 : 6|1@0+ (1,0) [0|0] "" Vector__XXX
 SG_ AMS_BalInfo_Stack_00_C05 : 5|1@0+ (1,0) [0|0] "" Vector__XXX
 SG_ AMS_BalInfo_Stack_00_C04 : 4|1@0+ (1,0) [0|0] "" Vector__XXX
 SG_ AMS_BalInfo_Stack_00_C03 : 3|1@0+ (1,0) [0|0] "" Vector__XXX
 SG_ AMS_BalInfo_Stack_00_C02 : 2|1@0+ (1,0) [0|0] "" Vector__XXX
 SG_ AMS_BalInfo_Stack_00_C01 : 1|1@0+ (1,0) [0|0] "" Vector__XXX
 SG_ AMS_BalInfo_Stack_00_C00 : 0|1@0+ (1,0) [0|0] "" Vector__XXX

BO_ 884 AMS_Bal_Info_Stack_4_7: 8 _04_HV_AMS
 SG_ AMS_BalInfo_Stack_07_C11 : 59|1@0+ (1,0) [0|0] "" Vector__XXX
 SG_ AMS_BalInfo_Stack_07_C10 : 58|1@0+ (1,0) [0|0] "" Vector__XXX
 SG_ AMS_BalInfo_Stack_07_C09 : 57|1@0+ (1,0) [0|0] "" Vector__XXX
 SG_ AMS_BalInfo_Stack_07_C08 : 56|1@0+ (1,0) [0|0] "" Vector__XXX
 SG_ AMS_BalInfo_Stack_07_C07 : 55|1@0+ (1,0) [0|0] "" Vector__XXX
 SG_ AMS_BalInfo_Stack_07_C06 : 54|1@0+ (1,0) [0|0] "" Vector__XXX
 SG_ AMS_BalInfo_Stack_07_C05 : 53|1@0+ (1,0) [0|0] "" Vector__XXX
 SG_ AMS_BalInfo_Stack_07_C04 : 52|1@0+ (1,0) [0|0] "" Vector__XXX
 SG_ AMS_BalInfo_Stack_07_C03 : 51|1@0+ (1,0) [0|0] "" Vector__XXX
 SG_ AMS_BalInfo_Stack_07_C02 : 50|1@0+ (1,0) [0|0] "" Vector__XXX
 SG_ AMS_BalInfo_Stack_07_C01 : 49|1@0+ (1,0) [0|0] "" Vector__XXX
 SG_ AMS_BalInfo_Stack_07_C00 : 48|1@0+ (1,0) [0|0] "" Vector__XXX
 SG_ AMS_BalInfo_Stack_06_C11 : 43|1@0+ (1,0) [0|0] "" Vector__XXX
 SG_ AMS_BalInfo_Stack_06_C10 : 42|1@0+ (1,0) [0|0] "" Vector__XXX
 SG_ AMS_BalInfo_Stack_06_C09 : 41|1@0+ (1,0) [0|0] "" Vector__XXX
 SG_ AMS_BalInfo_Stack_06_C08 : 40|1@0+ (1,0) [0|0] "" Vector__XXX
 SG_ AMS_BalInfo_Stack_06_C07 : 39|1@0+ (1,0) [0|0] "" Vector__XXX
 SG_ AMS_BalInfo_Stack_06_C06 : 38|1@0+ (1,0) [0|0] "" Vector__XXX
 SG_ AMS_BalInfo_Stack_06_C05 : 37|1@0+ (1,0) [0|0] "" Vector__XXX
 SG_ AMS_BalInfo_Stack_06_C04 : 36|1@0+ (1,0) [0|0] "" Vector__XXX
 SG_ AMS_BalInfo_Stack_06_C03 : 35|1@0+ (1,0) [0|0] "" Vector__XXX
 SG_ AMS_BalInfo_Stack_06_C02 : 34|1@0+ (1,0) [0|0] "" Vector__XXX
 SG_ AMS_BalInfo_Stack_06_C01 : 33|1@0+ (1,0) [0|0] "" Vector__XXX
 SG_ AMS_BalInfo_Stack_06_C00 : 32|1@0+ (1,0) [0|0] "" Vector__XXX
 SG_ AMS_BalInfo_Stack_05_C11 : 27|1@0+ (1,0) [0|0] "" Vector__XXX
 SG_ AMS_BalInfo_Stack_05_C10 : 26|1@0+ (1,0) [0|0] "" Vector__XXX
 SG_ AMS_BalInfo_Stack_05_C09 : 25|1@0+ (1,0) [0|0] "" Vector__XXX
 SG_ AMS_BalInfo_Stack_05_C08 : 24|1@0+ (1,0) [0|0] "" Vector__XXX
 SG_ AMS_BalInfo_Stack_05_C07 : 23|1@0+ (1,0) [0|0] "" Vector__XXX
 SG_ AMS_BalInfo_Stack_05_C06 : 22|1@0+ (1,0) [0|0] "" Vector__XXX
 SG_ AMS_BalInfo_Stack_05_C05 : 21|1@0+ (1,0) [0|0] "" Vector__XXX
 SG_ AMS_BalInfo_Stack_05_C04 : 20|1@0+ (1,0) [0|0] "" Vector__XXX
 SG_ AMS_BalInfo_Stack_05_C03 : 19|1@0+ (1,0) [0|0] "" Vector__XXX
 SG_ AMS_BalInfo_Stack_05_C02 : 18|1@0+ (1,0) [0|0] "" Vector__XXX
 SG_ AMS_BalInfo_Stack_05_C01 : 17|1@0+ (1,0) [0|0] "" Vector__XXX
 SG_ AMS_BalInfo_Stack_05_C00 : 16|1@0+ (1,0) [0|0] "" Vector__XXX
 SG_ AMS_BalInfo_Stack_04_C11 : 11|1@0+ (1,0) [0|0] "" Vector__XXX
 SG_ AMS_BalInfo_Stack_04_C10 : 10|1@0+ (1,0) [0|0] "" Vector__XXX
 SG_ AMS_BalInfo_Stack_04_C09 : 9|1@0+ (1,0) [0|0] "" Vector__XXX
 SG_ AMS_BalInfo_Stack_04_C08 : 8|1@0+ (1,0) [0|0] "" Vector__XXX
 SG_ AMS_BalInfo_Stack_04_C07 : 7|1@0+ (1,0) [0|0] "" Vector__XXX
 SG_ AMS_BalInfo_Stack_04_C06 : 6|1@0+ (1,0) [0|0] "" Vector__XXX
 SG_ AMS_BalInfo_Stack_04_C05 : 5|1@0+ (1,0) [0|0] "" Vector__XXX
 SG_ AMS_BalInfo_Stack_04_C04 : 4|1@0+ (1,0) [0|0] "" Vector__XXX
 SG_ AMS_BalInfo_Stack_04_C03 : 3|1@0+ (1,0) [0|0] "" Vector__XXX
 SG_ AMS_BalInfo_Stack_04_C02 : 2|1@0+ (1,0) [0|0] "" Vector__XXX
 SG_ AMS_BalInfo_Stack_04_C01 : 1|1@0+ (1,0) [0|0] "" Vector__XXX
 SG_ AMS_BalInfo_Stack_04_C00 : 0|1@0+ (1,0) [0|0] "" Vector__XXX

BO_ 900 AMS_Bal_Info_Stack_8_11: 6 _04_HV_AMS
 SG_ AMS_BalInfo_Stack_11_C11 : 59|1@0+ (1,0) [0|0] "" Vector__XXX
 SG_ AMS_BalInfo_Stack_11_C10 : 58|1@0+ (1,0) [0|0] "" Vector__XXX
 SG_ AMS_BalInfo_Stack_11_C09 : 57|1@0+ (1,0) [0|0] "" Vector__XXX
 SG_ AMS_BalInfo_Stack_11_C08 : 56|1@0+ (1,0) [0|0] "" Vector__XXX
 SG_ AMS_BalInfo_Stack_11_C07 : 55|1@0+ (1,0) [0|0] "" Vector__XXX
 SG_ AMS_BalInfo_Stack_11_C06 : 54|1@0+ (1,0) [0|0] "" Vector__XXX
 SG_ AMS_BalInfo_Stack_11_C05 : 53|1@0+ (1,0) [0|0] "" Vector__XXX
 SG_ AMS_BalInfo_Stack_11_C04 : 52|1@0+ (1,0) [0|0] "" Vector__XXX
 SG_ AMS_BalInfo_Stack_11_C03 : 51|1@0+ (1,0) [0|0] "" Vector__XXX
 SG_ AMS_BalInfo_Stack_11_C02 : 50|1@0+ (1,0) [0|0] "" Vector__XXX
 SG_ AMS_BalInfo_Stack_11_C01 : 49|1@0+ (1,0) [0|0] "" Vector__XXX
 SG_ AMS_BalInfo_Stack_11_C00 : 48|1@0+ (1,0) [0|0] "" Vector__XXX
 SG_ AMS_BalInfo_Stack_10_C11 : 43|1@0+ (1,0) [0|0] "" Vector__XXX
 SG_ AMS_BalInfo_Stack_10_C10 : 42|1@0+ (1,0) [0|0] "" Vector__XXX
 SG_ AMS_BalInfo_Stack_10_C09 : 41|1@0+ (1,0) [0|0] "" Vector__XXX
 SG_ AMS_BalInfo_Stack_10_C08 : 40|1@0+ (1,0) [0|0] "" Vector__XXX
 SG_ AMS_BalInfo_Stack_10_C07 : 39|1@0+ (1,0) [0|0] "" Vector__XXX
 SG_ AMS_BalInfo_Stack_10_C06 : 38|1@0+ (1,0) [0|0] "" Vector__XXX
 SG_ AMS_BalInfo_Stack_10_C05 : 37|1@0+ (1,0) [0|0] "" Vector__XXX
 SG_ AMS_BalInfo_Stack_10_C04 : 36|1@0+ (1,0) [0|0] "" Vector__XXX
 SG_ AMS_BalInfo_Stack_10_C03 : 35|1@0+ (1,0) [0|0] "" Vector__XXX
 SG_ AMS_BalInfo_Stack_10_C02 : 34|1@0+ (1,0) [0|0] "" Vector__XXX
 SG_ AMS_BalInfo_Stack_10_C01 : 33|1@0+ (1,0) [0|0] "" Vector__XXX
 SG_ AMS_BalInfo_Stack_10_C00 : 32|1@0+ (1,0) [0|0] "" Vector__XXX
 SG_ AMS_BalInfo_Stack_09_C11 : 27|1@0+ (1,0) [0|0] "" Vector__XXX
 SG_ AMS_BalInfo_Stack_09_C10 : 26|1@0+ (1,0) [0|0] "" Vector__XXX
 SG_ AMS_BalInfo_Stack_09_C09 : 25|1@0+ (1,0) [0|0] "" Vector__XXX
 SG_ AMS_BalInfo_Stack_09_C08 : 24|1@0+ (1,0) [0|0] "" Vector__XXX
 SG_ AMS_BalInfo_Stack_09_C07 : 23|1@0+ (1,0) [0|0] "" Vector__XXX
 SG_ AMS_BalInfo_Stack_09_C06 : 22|1@0+ (1,0) [0|0] "" Vector__XXX
 SG_ AMS_BalInfo_Stack_09_C05 : 21|1@0+ (1,0) [0|0] "" Vector__XXX
 SG_ AMS_BalInfo_Stack_09_C04 : 20|1@0+ (1,0) [0|0] "" Vector__XXX
 SG_ AMS_BalInfo_Stack_09_C03 : 19|1@0+ (1,0) [0|0] "" Vector__XXX
 SG_ AMS_BalInfo_Stack_09_C02 : 18|1@0+ (1,0) [0|0] "" Vector__XXX
 SG_ AMS_BalInfo_Stack_09_C01 : 17|1@0+ (1,0) [0|0] "" Vector__XXX
 SG_ AMS_BalInfo_Stack_09_C00 : 16|1@0+ (1,0) [0|0] "" Vector__XXX
 SG_ AMS_BalInfo_Stack_08_C11 : 11|1@0+ (1,0) [0|0] "" Vector__XXX
 SG_ AMS_BalInfo_Stack_08_C10 : 10|1@0+ (1,0) [0|0] "" Vector__XXX
 SG_ AMS_BalInfo_Stack_08_C09 : 9|1@0+ (1,0) [0|0] "" Vector__XXX
 SG_ AMS_BalInfo_Stack_08_C08 : 8|1@0+ (1,0) [0|0] "" Vector__XXX
 SG_ AMS_BalInfo_Stack_08_C07 : 7|1@0+ (1,0) [0|0] "" Vector__XXX
 SG_ AMS_BalInfo_Stack_08_C06 : 6|1@0+ (1,0) [0|0] "" Vector__XXX
 SG_ AMS_BalInfo_Stack_08_C05 : 5|1@0+ (1,0) [0|0] "" Vector__XXX
 SG_ AMS_BalInfo_Stack_08_C04 : 4|1@0+ (1,0) [0|0] "" Vector__XXX
 SG_ AMS_BalInfo_Stack_08_C03 : 3|1@0+ (1,0) [0|0] "" Vector__XXX
 SG_ AMS_BalInfo_Stack_08_C02 : 2|1@0+ (1,0) [0|0] "" Vector__XXX
 SG_ AMS_BalInfo_Stack_08_C01 : 1|1@0+ (1,0) [0|0] "" Vector__XXX
 SG_ AMS_BalInfo_Stack_08_C00 : 0|1@0+ (1,0) [0|0] "" Vector__XXX

EV_ EnvVar_AMS_Reset: 0 [0|1] "" 0 1 DUMMY_NODE_VECTOR0 Vector__XXX;

EV_ EnvVar_Stop_Charging: 0 [0|1] "" 0 2 DUMMY_NODE_VECTOR0 Vector__XXX;

EV_ EnvVar_Start_Charging: 0 [0|1] "" 0 3 DUMMY_NODE_VECTOR0 Vector__XXX;

EV_ EnvVar_StopBalancing: 0 [0|1] "" 0 4 DUMMY_NODE_VECTOR0 Vector__XXX;

EV_ EnvVar_StartBalancing: 0 [0|1] "" 0 5 DUMMY_NODE_VECTOR0 Vector__XXX;

CM_ BO_ 3221225472 "This is a message for not used signals, created by Vector CANdb++ DBC OLE DB Provider.";
